[part 5 of 6: package /MICROSAR/KeyM_swc/ComponentTypes]
AUTOSAR XML (schema 00049)
package /MICROSAR/KeyM_swc/ComponentTypes  (continued)
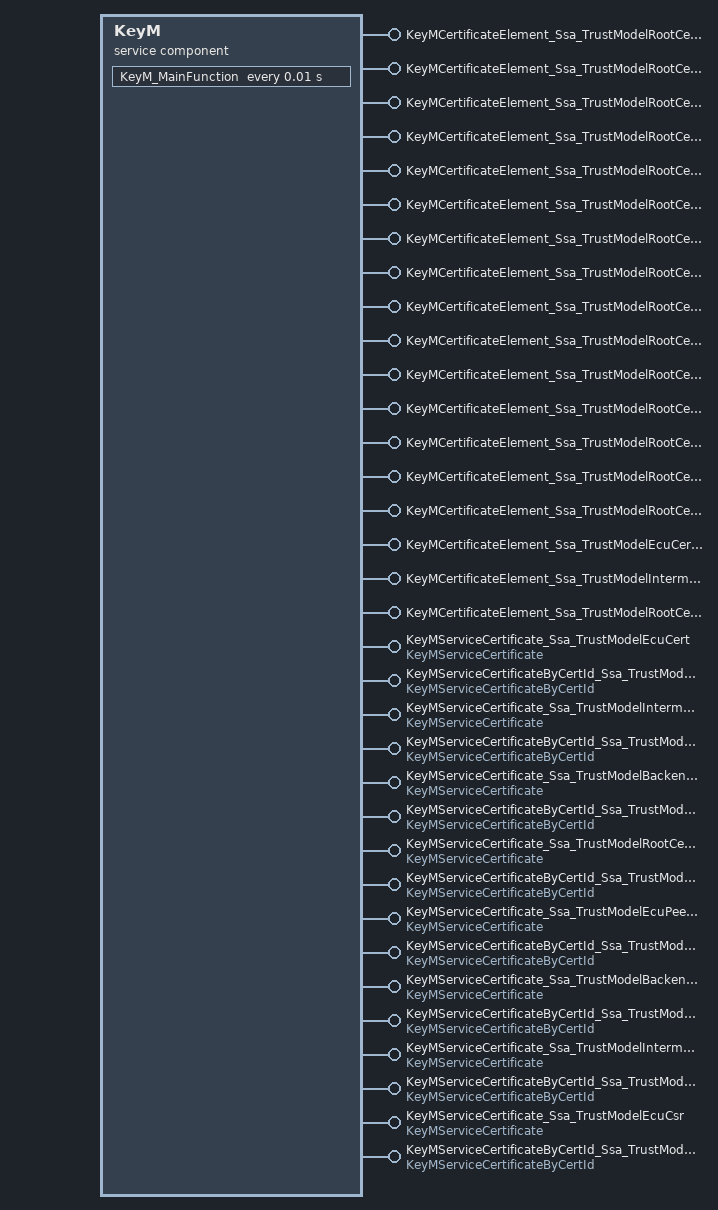
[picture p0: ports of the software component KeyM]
  service sw component type KeyM: category=SERVICE_COMPONENT  (continued)
    34 x provide port:
      KeyMCertificateElement_Ssa_TrustModelRootCert_Version: provided-interface=KeyMCertificateElement_Ssa_TrustModelRootCert_Version  # Port to execute certificate related functions.
      KeyMCertificateElement_Ssa_TrustModelRootCert_SerialNo: provided-interface=KeyMCertificateElement_Ssa_TrustModelRootCert_SerialNo  # Port to execute certificate related functions.
      KeyMCertificateElement_Ssa_TrustModelRootCert_SigAlgoId: provided-interface=KeyMCertificateElement_Ssa_TrustModelRootCert_SigAlgoId  # Port to execute certificate related functions.
      KeyMCertificateElement_Ssa_TrustModelRootCert_validityNotBefore: provided-interface=KeyMCertificateElement_Ssa_TrustModelRootCert_validityNotBefore  # Port to execute certificate related functions.
      KeyMCertificateElement_Ssa_TrustModelRootCert_validityNotAfter: provided-interface=KeyMCertificateElement_Ssa_TrustModelRootCert_validityNotAfter  # Port to execute certificate related functions.
      KeyMCertificateElement_Ssa_TrustModelRootCert_subject: provided-interface=KeyMCertificateElement_Ssa_TrustModelRootCert_subject  # Port to execute certificate related functions.
      KeyMCertificateElement_Ssa_TrustModelRootCert_SubjectPublicKeyInfoAlgo: provided-interface=KeyMCertificateElement_Ssa_TrustModelRootCert_SubjectPublicKeyInfoAlgo  # Port to execute certificate related functions.
      KeyMCertificateElement_Ssa_TrustModelRootCert_SubjectPublicKeyInfoKey: provided-interface=KeyMCertificateElement_Ssa_TrustModelRootCert_SubjectPublicKeyInfoKey  # Port to execute certificate related functions.
      KeyMCertificateElement_Ssa_TrustModelRootCert_Issuer: provided-interface=KeyMCertificateElement_Ssa_TrustModelRootCert_Issuer  # Port to execute certificate related functions.
      KeyMCertificateElement_Ssa_TrustModelRootCert_signatureAlgorithm: provided-interface=KeyMCertificateElement_Ssa_TrustModelRootCert_signatureAlgorithm  # Port to execute certificate related functions.
      KeyMCertificateElement_Ssa_TrustModelRootCert_signatureValue: provided-interface=KeyMCertificateElement_Ssa_TrustModelRootCert_signatureValue  # Port to execute certificate related functions.
      KeyMCertificateElement_Ssa_TrustModelRootCert_ext_subKeyId: provided-interface=KeyMCertificateElement_Ssa_TrustModelRootCert_ext_subKeyId  # Port to execute certificate related functions.
      KeyMCertificateElement_Ssa_TrustModelRootCert_ext_basicConstraints: provided-interface=KeyMCertificateElement_Ssa_TrustModelRootCert_ext_basicConstraints  # Port to execute certificate related functions.
      KeyMCertificateElement_Ssa_TrustModelRootCert_ext_keyUsage: provided-interface=KeyMCertificateElement_Ssa_TrustModelRootCert_ext_keyUsage  # Port to execute certificate related functions.
      KeyMCertificateElement_Ssa_TrustModelRootCert_ext_pkiRole: provided-interface=KeyMCertificateElement_Ssa_TrustModelRootCert_ext_pkiRole  # Port to execute certificate related functions.
      KeyMCertificateElement_Ssa_TrustModelEcuCert_ext_pkiRole_006: provided-interface=KeyMCertificateElement_Ssa_TrustModelEcuCert_ext_pkiRole_006  # Port to execute certificate related functions.
      KeyMCertificateElement_Ssa_TrustModelIntermediatePeerCert_ext_pkiRole_005: provided-interface=KeyMCertificateElement_Ssa_TrustModelIntermediatePeerCert_ext_pkiRole_005  # Port to execute certificate related functions.
      KeyMCertificateElement_Ssa_TrustModelRootCert_ext_authKeyId_009: provided-interface=KeyMCertificateElement_Ssa_TrustModelRootCert_ext_authKeyId_009  # Port to execute certificate related functions.
      KeyMServiceCertificate_Ssa_TrustModelEcuCert: provided-interface=KeyMServiceCertificate  # Port to execute certificate related functions.
      KeyMServiceCertificateByCertId_Ssa_TrustModelEcuCert: provided-interface=KeyMServiceCertificateByCertId  # Port to execute certificate related functions.
      KeyMServiceCertificate_Ssa_TrustModelIntermediateCert: provided-interface=KeyMServiceCertificate  # Port to execute certificate related functions.
      KeyMServiceCertificateByCertId_Ssa_TrustModelIntermediateCert: provided-interface=KeyMServiceCertificateByCertId  # Port to execute certificate related functions.
      KeyMServiceCertificate_Ssa_TrustModelBackendCert: provided-interface=KeyMServiceCertificate  # Port to execute certificate related functions.
      KeyMServiceCertificateByCertId_Ssa_TrustModelBackendCert: provided-interface=KeyMServiceCertificateByCertId  # Port to execute certificate related functions.
      KeyMServiceCertificate_Ssa_TrustModelRootCert: provided-interface=KeyMServiceCertificate  # Port to execute certificate related functions.
      KeyMServiceCertificateByCertId_Ssa_TrustModelRootCert: provided-interface=KeyMServiceCertificateByCertId  # Port to execute certificate related functions.
      KeyMServiceCertificate_Ssa_TrustModelEcuPeerCert: provided-interface=KeyMServiceCertificate  # Port to execute certificate related functions.
      KeyMServiceCertificateByCertId_Ssa_TrustModelEcuPeerCert: provided-interface=KeyMServiceCertificateByCertId  # Port to execute certificate related functions.
      KeyMServiceCertificate_Ssa_TrustModelBackendPeerCert: provided-interface=KeyMServiceCertificate  # Port to execute certificate related functions.
      KeyMServiceCertificateByCertId_Ssa_TrustModelBackendPeerCert: provided-interface=KeyMServiceCertificateByCertId  # Port to execute certificate related functions.
      KeyMServiceCertificate_Ssa_TrustModelIntermediatePeerCert: provided-interface=KeyMServiceCertificate  # Port to execute certificate related functions.
      KeyMServiceCertificateByCertId_Ssa_TrustModelIntermediatePeerCert: provided-interface=KeyMServiceCertificateByCertId  # Port to execute certificate related functions.
      KeyMServiceCertificate_Ssa_TrustModelEcuCsr: provided-interface=KeyMServiceCertificate  # Port to execute certificate related functions.
      KeyMServiceCertificateByCertId_Ssa_TrustModelEcuCsr: provided-interface=KeyMServiceCertificateByCertId  # Port to execute certificate related functions.
    behavior KeyMInternalBehavior: handle-termination-and-restart=NO-SUPPORT, included-data-type-set=data-type=[KeyM_CertElementIdType, KeyM_CertificateIdType, KeyM_const_CryptoKeyDataType, KeyM_CryptoKeyDataType, KeyM_ConstDataPtrType, KeyM_DataPtrType, KeyM_LengthPtrType, KeyM_CertDataPointerType, KeyM_CertDataType, KeyM_CsrEncodingType, KeyM_ServiceCertificateType, KeyM_CertificateStatusType, KeyM_ResultType, KeyM_CertificateDataType_Ssa_TrustModelEcuCert, KeyM_CertificateType_Ssa_TrustModelEcuCert, KeyM_CertificateElementType_Ssa_TrustModelEcuCert_ext_authKeyId_005, KeyM_CertificateElementType_Ssa_TrustModelEcuCert_ext_subKeyId_005, KeyM_CertificateElementType_Ssa_TrustModelEcuCert_ext_keyUsage_005, KeyM_CertificateElementType_Ssa_TrustModelEcuCert_ext_pkiRole_006, KeyM_CertificateElementType_Ssa_TrustModelEcuCert_Version_005, KeyM_CertificateElementType_Ssa_TrustModelEcuCert_SerialNo_005, KeyM_CertificateElementType_Ssa_TrustModelEcuCert_SigAlgoId_005, KeyM_CertificateElementType_Ssa_TrustModelEcuCert_validityNotBefore_005, KeyM_CertificateElementType_Ssa_TrustModelEcuCert_validityNotAfter_005, KeyM_CertificateElementType_Ssa_TrustModelEcuCert_subject_005, KeyM_CertificateElementType_Ssa_TrustModelEcuCert_SubjectPublicKeyInfoAlgo_005, KeyM_CertificateElementType_Ssa_TrustModelEcuCert_SubjectPublicKeyInfoKey_005, KeyM_CertificateElementType_Ssa_TrustModelEcuCert_Issuer_005, KeyM_CertificateElementType_Ssa_TrustModelEcuCert_signatureAlgorithm_005, KeyM_CertificateElementType_Ssa_TrustModelEcuCert_signatureValue_005, KeyM_CertificateElementType_Ssa_TrustModelEcuCert_ext_uniqueECUID_005, KeyM_CertificateElementType_Ssa_TrustModelEcuCert_ext_specialEcu_005, KeyM_CertificateDataType_Ssa_TrustModelIntermediateCert, KeyM_CertificateType_Ssa_TrustModelIntermediateCert, KeyM_CertificateElementType_Ssa_TrustModelIntermediateCert_ext_authKeyId_003, KeyM_CertificateElementType_Ssa_TrustModelIntermediateCert_ext_subKeyId_003, KeyM_CertificateElementType_Ssa_TrustModelIntermediateCert_ext_basicConstraints_003, KeyM_CertificateElementType_Ssa_TrustModelIntermediateCert_ext_keyUsage_003, KeyM_CertificateElementType_Ssa_TrustModelIntermediateCert_ext_pkiRole_003, KeyM_CertificateElementType_Ssa_TrustModelIntermediateCert_Version_003, KeyM_CertificateElementType_Ssa_TrustModelIntermediateCert_SerialNo_003, KeyM_CertificateElementType_Ssa_TrustModelIntermediateCert_SigAlgoId_003, KeyM_CertificateElementType_Ssa_TrustModelIntermediateCert_validityNotBefore_003, KeyM_CertificateElementType_Ssa_TrustModelIntermediateCert_validityNotAfter_003, KeyM_CertificateElementType_Ssa_TrustModelIntermediateCert_subject_003, KeyM_CertificateElementType_Ssa_TrustModelIntermediateCert_SubjectPublicKeyInfoAlgo_003, KeyM_CertificateElementType_Ssa_TrustModelIntermediateCert_SubjectPublicKeyInfoKey_003, KeyM_CertificateElementType_Ssa_TrustModelIntermediateCert_Issuer_003, KeyM_CertificateElementType_Ssa_TrustModelIntermediateCert_signatureAlgorithm_003, KeyM_CertificateElementType_Ssa_TrustModelIntermediateCert_signatureValue_003, KeyM_CertificateDataType_Ssa_TrustModelBackendCert, KeyM_CertificateType_Ssa_TrustModelBackendCert, KeyM_CertificateElementType_Ssa_TrustModelBackendCert_ext_authKeyId_002, KeyM_CertificateElementType_Ssa_TrustModelBackendCert_ext_subKeyId_002, KeyM_CertificateElementType_Ssa_TrustModelBackendCert_ext_basicConstraints_002, KeyM_CertificateElementType_Ssa_TrustModelBackendCert_ext_keyUsage_002, KeyM_CertificateElementType_Ssa_TrustModelBackendCert_ext_pkiRole_002, KeyM_CertificateElementType_Ssa_TrustModelBackendCert_Version_002, KeyM_CertificateElementType_Ssa_TrustModelBackendCert_SerialNo_002, KeyM_CertificateElementType_Ssa_TrustModelBackendCert_SigAlgoId_002, KeyM_CertificateElementType_Ssa_TrustModelBackendCert_validityNotBefore_002, KeyM_CertificateElementType_Ssa_TrustModelBackendCert_validityNotAfter_002, KeyM_CertificateElementType_Ssa_TrustModelBackendCert_subject_002, KeyM_CertificateElementType_Ssa_TrustModelBackendCert_SubjectPublicKeyInfoAlgo_002, KeyM_CertificateElementType_Ssa_TrustModelBackendCert_SubjectPublicKeyInfoKey_002, KeyM_CertificateElementType_Ssa_TrustModelBackendCert_Issuer_002, KeyM_CertificateElementType_Ssa_TrustModelBackendCert_signatureAlgorithm_002, KeyM_CertificateElementType_Ssa_TrustModelBackendCert_signatureValue_002, KeyM_CertificateDataType_Ssa_TrustModelRootCert, KeyM_CertificateType_Ssa_TrustModelRootCert, KeyM_CertificateElementType_Ssa_TrustModelRootCert_ext_authKeyId_009, KeyM_CertificateElementType_Ssa_TrustModelRootCert_Version, KeyM_CertificateElementType_Ssa_TrustModelRootCert_SerialNo, KeyM_CertificateElementType_Ssa_TrustModelRootCert_SigAlgoId, KeyM_CertificateElementType_Ssa_TrustModelRootCert_validityNotBefore, KeyM_CertificateElementType_Ssa_TrustModelRootCert_validityNotAfter, KeyM_CertificateElementType_Ssa_TrustModelRootCert_subject, KeyM_CertificateElementType_Ssa_TrustModelRootCert_SubjectPublicKeyInfoAlgo, KeyM_CertificateElementType_Ssa_TrustModelRootCert_SubjectPublicKeyInfoKey, KeyM_CertificateElementType_Ssa_TrustModelRootCert_Issuer, KeyM_CertificateElementType_Ssa_TrustModelRootCert_signatureAlgorithm, KeyM_CertificateElementType_Ssa_TrustModelRootCert_signatureValue, KeyM_CertificateElementType_Ssa_TrustModelRootCert_ext_subKeyId, KeyM_CertificateElementType_Ssa_TrustModelRootCert_ext_basicConstraints, KeyM_CertificateElementType_Ssa_TrustModelRootCert_ext_keyUsage, KeyM_CertificateElementType_Ssa_TrustModelRootCert_ext_pkiRole, KeyM_CertificateDataType_Ssa_TrustModelEcuPeerCert, KeyM_CertificateType_Ssa_TrustModelEcuPeerCert, KeyM_CertificateElementType_Ssa_TrustModelEcuPeerCert_ext_authKeyId_006, KeyM_CertificateElementType_Ssa_TrustModelEcuPeerCert_ext_subKeyId_006, KeyM_CertificateElementType_Ssa_TrustModelEcuPeerCert_ext_keyUsage_006, KeyM_CertificateElementType_Ssa_TrustModelEcuPeerCert_Version_006, KeyM_CertificateElementType_Ssa_TrustModelEcuPeerCert_SerialNo_006, KeyM_CertificateElementType_Ssa_TrustModelEcuPeerCert_SigAlgoId_006, KeyM_CertificateElementType_Ssa_TrustModelEcuPeerCert_validityNotBefore_006, KeyM_CertificateElementType_Ssa_TrustModelEcuPeerCert_validityNotAfter_006, KeyM_CertificateElementType_Ssa_TrustModelEcuPeerCert_subject_006, KeyM_CertificateElementType_Ssa_TrustModelEcuPeerCert_SubjectPublicKeyInfoAlgo_006, KeyM_CertificateElementType_Ssa_TrustModelEcuPeerCert_SubjectPublicKeyInfoKey_006, KeyM_CertificateElementType_Ssa_TrustModelEcuPeerCert_Issuer_006, KeyM_CertificateElementType_Ssa_TrustModelEcuPeerCert_signatureAlgorithm_006, KeyM_CertificateElementType_Ssa_TrustModelEcuPeerCert_signatureValue_006, KeyM_CertificateElementType_Ssa_TrustModelEcuPeerCert_ext_uniqueECUID_006, KeyM_CertificateElementType_Ssa_TrustModelEcuPeerCert_ext_specialEcu_006, KeyM_CertificateDataType_Ssa_TrustModelBackendPeerCert, KeyM_CertificateType_Ssa_TrustModelBackendPeerCert, KeyM_CertificateElementType_Ssa_TrustModelBackendPeerCert_ext_authKeyId_004, KeyM_CertificateElementType_Ssa_TrustModelBackendPeerCert_ext_subKeyId_004, KeyM_CertificateElementType_Ssa_TrustModelBackendPeerCert_ext_basicConstraints_004, KeyM_CertificateElementType_Ssa_TrustModelBackendPeerCert_ext_keyUsage_004, KeyM_CertificateElementType_Ssa_TrustModelBackendPeerCert_ext_pkiRole_004, KeyM_CertificateElementType_Ssa_TrustModelBackendPeerCert_Version_004, KeyM_CertificateElementType_Ssa_TrustModelBackendPeerCert_SerialNo_004, KeyM_CertificateElementType_Ssa_TrustModelBackendPeerCert_SigAlgoId_004, KeyM_CertificateElementType_Ssa_TrustModelBackendPeerCert_validityNotBefore_004, KeyM_CertificateElementType_Ssa_TrustModelBackendPeerCert_validityNotAfter_004, KeyM_CertificateElementType_Ssa_TrustModelBackendPeerCert_subject_004, KeyM_CertificateElementType_Ssa_TrustModelBackendPeerCert_SubjectPublicKeyInfoAlgo_004, KeyM_CertificateElementType_Ssa_TrustModelBackendPeerCert_SubjectPublicKeyInfoKey_004, KeyM_CertificateElementType_Ssa_TrustModelBackendPeerCert_Issuer_004, KeyM_CertificateElementType_Ssa_TrustModelBackendPeerCert_signatureAlgorithm_004, KeyM_CertificateElementType_Ssa_TrustModelBackendPeerCert_signatureValue_004, KeyM_CertificateDataType_Ssa_TrustModelIntermediatePeerCert, KeyM_CertificateType_Ssa_TrustModelIntermediatePeerCert, KeyM_CertificateElementType_Ssa_TrustModelIntermediatePeerCert_ext_authKeyId_007, KeyM_CertificateElementType_Ssa_TrustModelIntermediatePeerCert_ext_subKeyId_007, KeyM_CertificateElementType_Ssa_TrustModelIntermediatePeerCert_ext_basicConstraints_005, KeyM_CertificateElementType_Ssa_TrustModelIntermediatePeerCert_ext_keyUsage_007, KeyM_CertificateElementType_Ssa_TrustModelIntermediatePeerCert_ext_pkiRole_005, KeyM_CertificateElementType_Ssa_TrustModelIntermediatePeerCert_Version_007, KeyM_CertificateElementType_Ssa_TrustModelIntermediatePeerCert_SerialNo_007, KeyM_CertificateElementType_Ssa_TrustModelIntermediatePeerCert_SigAlgoId_007, KeyM_CertificateElementType_Ssa_TrustModelIntermediatePeerCert_validityNotBefore_007, KeyM_CertificateElementType_Ssa_TrustModelIntermediatePeerCert_validityNotAfter_007, KeyM_CertificateElementType_Ssa_TrustModelIntermediatePeerCert_subject_007, KeyM_CertificateElementType_Ssa_TrustModelIntermediatePeerCert_SubjectPublicKeyInfoAlgo_007, KeyM_CertificateElementType_Ssa_TrustModelIntermediatePeerCert_SubjectPublicKeyInfoKey_007, KeyM_CertificateElementType_Ssa_TrustModelIntermediatePeerCert_Issuer_007, KeyM_CertificateElementType_Ssa_TrustModelIntermediatePeerCert_signatureAlgorithm_007, KeyM_CertificateElementType_Ssa_TrustModelIntermediatePeerCert_signatureValue_007, KeyM_CertificateDataType_Ssa_TrustModelEcuCsr, KeyM_CertificateType_Ssa_TrustModelEcuCsr, KeyM_CertificateElementType_Ssa_TrustModelEcuCsr_ext_authKeyId_008, KeyM_CertificateElementType_Ssa_TrustModelEcuCsr_ext_subKeyId_008, KeyM_CertificateElementType_Ssa_TrustModelEcuCsr_ext_keyUsage_008, KeyM_CertificateElementType_Ssa_TrustModelEcuCsr_ext_pkiRole_008, KeyM_CertificateElementType_Ssa_TrustModelEcuCsr_Version_008, KeyM_CertificateElementType_Ssa_TrustModelEcuCsr_SerialNo_008, KeyM_CertificateElementType_Ssa_TrustModelEcuCsr_SigAlgoId_008, KeyM_CertificateElementType_Ssa_TrustModelEcuCsr_validityNotBefore_008, KeyM_CertificateElementType_Ssa_TrustModelEcuCsr_validityNotAfter_008, KeyM_CertificateElementType_Ssa_TrustModelEcuCsr_subject_008, KeyM_CertificateElementType_Ssa_TrustModelEcuCsr_SubjectPublicKeyInfoAlgo_008, KeyM_CertificateElementType_Ssa_TrustModelEcuCsr_SubjectPublicKeyInfoKey_008, KeyM_CertificateElementType_Ssa_TrustModelEcuCsr_Issuer_008, KeyM_CertificateElementType_Ssa_TrustModelEcuCsr_signatureAlgorithm_008, KeyM_CertificateElementType_Ssa_TrustModelEcuCsr_signatureValue_008, KeyM_CertificateElementType_Ssa_TrustModelEcuCsr_ext_uniqueECUID_007, KeyM_CertificateElementType_Ssa_TrustModelEcuCsr_ext_specialEcu_007, KeyM_CertificateElementType_Ssa_TrustModelEcuCsr_ext_extKeyUsage_007, KeyM_CertificateElementType_Ssa_TrustModelEcuCsr_ext_extKeyUsage_oid1_007, KeyM_CertificateElementType_Ssa_TrustModelEcuCsr_ext_extKeyUsage_oid2_007, KeyM_CertificateElementType_Ssa_TrustModelEcuCsr_ext_extKeyUsage_oid3_007]
      timing event Timer_KeyM_MainFunction: start-on-event=KeyM_MainFunction, period=0.01
      466 x operation invoked event:
        OpEventGetCertificate_Ssa_TrustModelBackendCert_GetCertificate_KeyMCertificate_Ssa_TrustModelBackendCert: start-on-event=GetCertificate_Ssa_TrustModelBackendCert, operation=KeyMCertificate_Ssa_TrustModelBackendCert.GetCertificate
        OpEventCertificateElementGetCount_CertificateElementGetCount_KeyMCertificateElement_Ssa_TrustModelIntermediatePeerCert_b8bfbe9c: start-on-event=CertificateElementGetCount, operation=KeyMCertificateElement_Ssa_TrustModelIntermediatePeerCert_SubjectPublicKeyInfoAlgo_007.CertificateElementGetCount
        OpEventCertificateElementGetCount_CertificateElementGetCount_KeyMCertificateElement_Ssa_TrustModelEcuCert_signatureAlgorithm_005: start-on-event=CertificateElementGetCount, operation=KeyMCertificateElement_Ssa_TrustModelEcuCert_signatureAlgorithm_005.CertificateElementGetCount
        OpEventCertificateElementGetCount_CertificateElementGetCount_KeyMCertificateElement_Ssa_TrustModelEcuCsr_ext_specialEcu_007: start-on-event=CertificateElementGetCount, operation=KeyMCertificateElement_Ssa_TrustModelEcuCsr_ext_specialEcu_007.CertificateElementGetCount
        OpEventCertificateElementGetCount_CertificateElementGetCount_KeyMCertificateElement_Ssa_TrustModelEcuPeerCert_ext_keyUsage_006: start-on-event=CertificateElementGetCount, operation=KeyMCertificateElement_Ssa_TrustModelEcuPeerCert_ext_keyUsage_006.CertificateElementGetCount
        OpEventCertificateElementGetCount_CertificateElementGetCount_KeyMCertificateElement_Ssa_TrustModelEcuCsr_ext_authKeyId_008: start-on-event=CertificateElementGetCount, operation=KeyMCertificateElement_Ssa_TrustModelEcuCsr_ext_authKeyId_008.CertificateElementGetCount
        OpEventCertificateElementGetCount_CertificateElementGetCount_KeyMCertificateElement_Ssa_TrustModelEcuCsr_SerialNo_008: start-on-event=CertificateElementGetCount, operation=KeyMCertificateElement_Ssa_TrustModelEcuCsr_SerialNo_008.CertificateElementGetCount
        OpEventCertificateElementGetCount_CertificateElementGetCount_KeyMCertificateElement_Ssa_TrustModelIntermediatePeerCert_69e38857: start-on-event=CertificateElementGetCount, operation=KeyMCertificateElement_Ssa_TrustModelIntermediatePeerCert_Issuer_007.CertificateElementGetCount
        OpEventCertificateElementGetCount_CertificateElementGetCount_KeyMCertificateElement_Ssa_TrustModelIntermediatePeerCert_981aecb6: start-on-event=CertificateElementGetCount, operation=KeyMCertificateElement_Ssa_TrustModelIntermediatePeerCert_ext_subKeyId_007.CertificateElementGetCount
        OpEventCertificateElementGetCount_CertificateElementGetCount_KeyMCertificateElement_Ssa_TrustModelBackendPeerCert_Version_004: start-on-event=CertificateElementGetCount, operation=KeyMCertificateElement_Ssa_TrustModelBackendPeerCert_Version_004.CertificateElementGetCount
        OpEventCertificateElementGetCount_CertificateElementGetCount_KeyMCertificateElement_Ssa_TrustModelIntermediatePeerCert_14bdc58e: start-on-event=CertificateElementGetCount, operation=KeyMCertificateElement_Ssa_TrustModelIntermediatePeerCert_subject_007.CertificateElementGetCount
        OpEventCertificateElementGetCount_CertificateElementGetCount_KeyMCertificateElement_Ssa_TrustModelBackendCert_ext_authKeyId_002: start-on-event=CertificateElementGetCount, operation=KeyMCertificateElement_Ssa_TrustModelBackendCert_ext_authKeyId_002.CertificateElementGetCount
        OpEventCertificateElementGetCount_CertificateElementGetCount_KeyMCertificateElement_Ssa_TrustModelIntermediateCert_Version_003: start-on-event=CertificateElementGetCount, operation=KeyMCertificateElement_Ssa_TrustModelIntermediateCert_Version_003.CertificateElementGetCount
        OpEventCertificateElementGetCount_CertificateElementGetCount_KeyMCertificateElement_Ssa_TrustModelBackendCert_SubjectPu_e89d2572: start-on-event=CertificateElementGetCount, operation=KeyMCertificateElement_Ssa_TrustModelBackendCert_SubjectPublicKeyInfoKey_002.CertificateElementGetCount
        OpEventCertificateElementGetCount_CertificateElementGetCount_KeyMCertificateElement_Ssa_TrustModelEcuCsr_SubjectPublicK_4f39b0de: start-on-event=CertificateElementGetCount, operation=KeyMCertificateElement_Ssa_TrustModelEcuCsr_SubjectPublicKeyInfoKey_008.CertificateElementGetCount
        OpEventCertificateElementGetCount_CertificateElementGetCount_KeyMCertificateElement_Ssa_TrustModelBackendPeerCert_ext_a_7070e89e: start-on-event=CertificateElementGetCount, operation=KeyMCertificateElement_Ssa_TrustModelBackendPeerCert_ext_authKeyId_004.CertificateElementGetCount
        OpEventCertificateElementGetCount_CertificateElementGetCount_KeyMCertificateElement_Ssa_TrustModelBackendCert_validityN_9a428a85: start-on-event=CertificateElementGetCount, operation=KeyMCertificateElement_Ssa_TrustModelBackendCert_validityNotAfter_002.CertificateElementGetCount
        OpEventCertificateElementGetCount_CertificateElementGetCount_KeyMCertificateElement_Ssa_TrustModelIntermediateCert_Subj_7b37ce18: start-on-event=CertificateElementGetCount, operation=KeyMCertificateElement_Ssa_TrustModelIntermediateCert_SubjectPublicKeyInfoAlgo_003.CertificateElementGetCount
        OpEventCertificateElementGetCount_CertificateElementGetCount_KeyMCertificateElement_Ssa_TrustModelBackendCert_signature_37dbcc1b: start-on-event=CertificateElementGetCount, operation=KeyMCertificateElement_Ssa_TrustModelBackendCert_signatureAlgorithm_002.CertificateElementGetCount
        OpEventCertificateElementGetCount_CertificateElementGetCount_KeyMCertificateElement_Ssa_TrustModelIntermediateCert_SerialNo_003: start-on-event=CertificateElementGetCount, operation=KeyMCertificateElement_Ssa_TrustModelIntermediateCert_SerialNo_003.CertificateElementGetCount
        OpEventCertificateElementGetCount_CertificateElementGetCount_KeyMCertificateElement_Ssa_TrustModelIntermediateCert_ext_6b458183: start-on-event=CertificateElementGetCount, operation=KeyMCertificateElement_Ssa_TrustModelIntermediateCert_ext_basicConstraints_003.CertificateElementGetCount
        OpEventCertificateElementGetCount_CertificateElementGetCount_KeyMCertificateElement_Ssa_TrustModelEcuCert_Issuer_005: start-on-event=CertificateElementGetCount, operation=KeyMCertificateElement_Ssa_TrustModelEcuCert_Issuer_005.CertificateElementGetCount
        OpEventCertificateElementGetCount_CertificateElementGetCount_KeyMCertificateElement_Ssa_TrustModelEcuPeerCert_ext_uniqu_19d8752c: start-on-event=CertificateElementGetCount, operation=KeyMCertificateElement_Ssa_TrustModelEcuPeerCert_ext_uniqueECUID_006.CertificateElementGetCount
        OpEventCertificateElementGetCount_CertificateElementGetCount_KeyMCertificateElement_Ssa_TrustModelBackendCert_SigAlgoId_002: start-on-event=CertificateElementGetCount, operation=KeyMCertificateElement_Ssa_TrustModelBackendCert_SigAlgoId_002.CertificateElementGetCount
        OpEventCertificateElementGetCount_CertificateElementGetCount_KeyMCertificateElement_Ssa_TrustModelBackendCert_ext_subKeyId_002: start-on-event=CertificateElementGetCount, operation=KeyMCertificateElement_Ssa_TrustModelBackendCert_ext_subKeyId_002.CertificateElementGetCount
        OpEventCertificateElementGetCount_CertificateElementGetCount_KeyMCertificateElement_Ssa_TrustModelBackendCert_subject_002: start-on-event=CertificateElementGetCount, operation=KeyMCertificateElement_Ssa_TrustModelBackendCert_subject_002.CertificateElementGetCount
        OpEventCertificateElementGetCount_CertificateElementGetCount_KeyMCertificateElement_Ssa_TrustModelBackendPeerCert_ext_k_87711b19: start-on-event=CertificateElementGetCount, operation=KeyMCertificateElement_Ssa_TrustModelBackendPeerCert_ext_keyUsage_004.CertificateElementGetCount
        OpEventCertificateElementGetCount_CertificateElementGetCount_KeyMCertificateElement_Ssa_TrustModelBackendPeerCert_Subje_4bbc2c66: start-on-event=CertificateElementGetCount, operation=KeyMCertificateElement_Ssa_TrustModelBackendPeerCert_SubjectPublicKeyInfoKey_004.CertificateElementGetCount
        OpEventCertificateElementGetCount_CertificateElementGetCount_KeyMCertificateElement_Ssa_TrustModelEcuCsr_validityNotAfter_008: start-on-event=CertificateElementGetCount, operation=KeyMCertificateElement_Ssa_TrustModelEcuCsr_validityNotAfter_008.CertificateElementGetCount
        OpEventCertificateElementGetCount_CertificateElementGetCount_KeyMCertificateElement_Ssa_TrustModelEcuCert_validityNotBefore_005: start-on-event=CertificateElementGetCount, operation=KeyMCertificateElement_Ssa_TrustModelEcuCert_validityNotBefore_005.CertificateElementGetCount
        OpEventCertificateElementGetCount_CertificateElementGetCount_KeyMCertificateElement_Ssa_TrustModelBackendPeerCert_subject_004: start-on-event=CertificateElementGetCount, operation=KeyMCertificateElement_Ssa_TrustModelBackendPeerCert_subject_004.CertificateElementGetCount
        OpEventCertificateElementGetCount_CertificateElementGetCount_KeyMCertificateElement_Ssa_TrustModelBackendPeerCert_SigAlgoId_004: start-on-event=CertificateElementGetCount, operation=KeyMCertificateElement_Ssa_TrustModelBackendPeerCert_SigAlgoId_004.CertificateElementGetCount
        OpEventCertificateElementGetCount_CertificateElementGetCount_KeyMCertificateElement_Ssa_TrustModelIntermediateCert_sign_5f19d28f: start-on-event=CertificateElementGetCount, operation=KeyMCertificateElement_Ssa_TrustModelIntermediateCert_signatureAlgorithm_003.CertificateElementGetCount
        OpEventCertificateElementGetCount_CertificateElementGetCount_KeyMCertificateElement_Ssa_TrustModelIntermediatePeerCert_7df9f6ad: start-on-event=CertificateElementGetCount, operation=KeyMCertificateElement_Ssa_TrustModelIntermediatePeerCert_validityNotAfter_007.CertificateElementGetCount
        OpEventCertificateElementGetCount_CertificateElementGetCount_KeyMCertificateElement_Ssa_TrustModelIntermediateCert_Issuer_003: start-on-event=CertificateElementGetCount, operation=KeyMCertificateElement_Ssa_TrustModelIntermediateCert_Issuer_003.CertificateElementGetCount
        OpEventCertificateElementGetCount_CertificateElementGetCount_KeyMCertificateElement_Ssa_TrustModelBackendPeerCert_Subje_cca0c35e: start-on-event=CertificateElementGetCount, operation=KeyMCertificateElement_Ssa_TrustModelBackendPeerCert_SubjectPublicKeyInfoAlgo_004.CertificateElementGetCount
        OpEventCertificateElementGetCount_CertificateElementGetCount_KeyMCertificateElement_Ssa_TrustModelEcuPeerCert_validityN_7ebdb999: start-on-event=CertificateElementGetCount, operation=KeyMCertificateElement_Ssa_TrustModelEcuPeerCert_validityNotAfter_006.CertificateElementGetCount
        OpEventCertificateElementGetCount_CertificateElementGetCount_KeyMCertificateElement_Ssa_TrustModelIntermediatePeerCert_a514cd03: start-on-event=CertificateElementGetCount, operation=KeyMCertificateElement_Ssa_TrustModelIntermediatePeerCert_ext_basicConstraints_005.CertificateElementGetCount
        OpEventCertificateElementGetCount_CertificateElementGetCount_KeyMCertificateElement_Ssa_TrustModelEcuCsr_ext_pkiRole_008: start-on-event=CertificateElementGetCount, operation=KeyMCertificateElement_Ssa_TrustModelEcuCsr_ext_pkiRole_008.CertificateElementGetCount
        OpEventCertificateElementGetCount_CertificateElementGetCount_KeyMCertificateElement_Ssa_TrustModelBackendPeerCert_Issuer_004: start-on-event=CertificateElementGetCount, operation=KeyMCertificateElement_Ssa_TrustModelBackendPeerCert_Issuer_004.CertificateElementGetCount
        OpEventCertificateElementGetCount_CertificateElementGetCount_KeyMCertificateElement_Ssa_TrustModelEcuPeerCert_SerialNo_006: start-on-event=CertificateElementGetCount, operation=KeyMCertificateElement_Ssa_TrustModelEcuPeerCert_SerialNo_006.CertificateElementGetCount
        OpEventCertificateElementGetCount_CertificateElementGetCount_KeyMCertificateElement_Ssa_TrustModelEcuCert_signatureValue_005: start-on-event=CertificateElementGetCount, operation=KeyMCertificateElement_Ssa_TrustModelEcuCert_signatureValue_005.CertificateElementGetCount
        OpEventCertificateElementGetCount_CertificateElementGetCount_KeyMCertificateElement_Ssa_TrustModelBackendPeerCert_SerialNo_004: start-on-event=CertificateElementGetCount, operation=KeyMCertificateElement_Ssa_TrustModelBackendPeerCert_SerialNo_004.CertificateElementGetCount
        OpEventCertificateElementGetCount_CertificateElementGetCount_KeyMCertificateElement_Ssa_TrustModelEcuCert_ext_specialEcu_005: start-on-event=CertificateElementGetCount, operation=KeyMCertificateElement_Ssa_TrustModelEcuCert_ext_specialEcu_005.CertificateElementGetCount
        OpEventCertificateElementGetCount_CertificateElementGetCount_KeyMCertificateElement_Ssa_TrustModelEcuCert_ext_authKeyId_005: start-on-event=CertificateElementGetCount, operation=KeyMCertificateElement_Ssa_TrustModelEcuCert_ext_authKeyId_005.CertificateElementGetCount
        OpEventCertificateElementGetCount_CertificateElementGetCount_KeyMCertificateElement_Ssa_TrustModelEcuPeerCert_validityN_02cfe267: start-on-event=CertificateElementGetCount, operation=KeyMCertificateElement_Ssa_TrustModelEcuPeerCert_validityNotBefore_006.CertificateElementGetCount
        OpEventCertificateElementGetCount_CertificateElementGetCount_KeyMCertificateElement_Ssa_TrustModelEcuCsr_ext_subKeyId_008: start-on-event=CertificateElementGetCount, operation=KeyMCertificateElement_Ssa_TrustModelEcuCsr_ext_subKeyId_008.CertificateElementGetCount
        OpEventCertificateElementGetCount_CertificateElementGetCount_KeyMCertificateElement_Ssa_TrustModelIntermediateCert_sign_e7bcb03d: start-on-event=CertificateElementGetCount, operation=KeyMCertificateElement_Ssa_TrustModelIntermediateCert_signatureValue_003.CertificateElementGetCount
        OpEventCertificateElementGetCount_CertificateElementGetCount_KeyMCertificateElement_Ssa_TrustModelBackendPeerCert_ext_b_b7c33782: start-on-event=CertificateElementGetCount, operation=KeyMCertificateElement_Ssa_TrustModelBackendPeerCert_ext_basicConstraints_004.CertificateElementGetCount
        OpEventCertificateElementGetCount_CertificateElementGetCount_KeyMCertificateElement_Ssa_TrustModelBackendPeerCert_signa_7fc2525c: start-on-event=CertificateElementGetCount, operation=KeyMCertificateElement_Ssa_TrustModelBackendPeerCert_signatureAlgorithm_004.CertificateElementGetCount
        OpEventCertificateElementGetCount_CertificateElementGetCount_KeyMCertificateElement_Ssa_TrustModelBackendCert_signatureValue_002: start-on-event=CertificateElementGetCount, operation=KeyMCertificateElement_Ssa_TrustModelBackendCert_signatureValue_002.CertificateElementGetCount
        OpEventCertificateElementGetCount_CertificateElementGetCount_KeyMCertificateElement_Ssa_TrustModelEcuCsr_Version_008: start-on-event=CertificateElementGetCount, operation=KeyMCertificateElement_Ssa_TrustModelEcuCsr_Version_008.CertificateElementGetCount
        OpEventCertificateElementGetCount_CertificateElementGetCount_KeyMCertificateElement_Ssa_TrustModelEcuCert_SerialNo_005: start-on-event=CertificateElementGetCount, operation=KeyMCertificateElement_Ssa_TrustModelEcuCert_SerialNo_005.CertificateElementGetCount
        OpEventCertificateElementGetCount_CertificateElementGetCount_KeyMCertificateElement_Ssa_TrustModelIntermediatePeerCert_6997f770: start-on-event=CertificateElementGetCount, operation=KeyMCertificateElement_Ssa_TrustModelIntermediatePeerCert_ext_keyUsage_007.CertificateElementGetCount
        OpEventCertificateElementGetCount_CertificateElementGetCount_KeyMCertificateElement_Ssa_TrustModelEcuCsr_signatureAlgorithm_008: start-on-event=CertificateElementGetCount, operation=KeyMCertificateElement_Ssa_TrustModelEcuCsr_signatureAlgorithm_008.CertificateElementGetCount
        OpEventCertificateElementGetCount_CertificateElementGetCount_KeyMCertificateElement_Ssa_TrustModelBackendCert_validityN_752b4006: start-on-event=CertificateElementGetCount, operation=KeyMCertificateElement_Ssa_TrustModelBackendCert_validityNotBefore_002.CertificateElementGetCount
        OpEventCertificateElementGetCount_CertificateElementGetCount_KeyMCertificateElement_Ssa_TrustModelEcuPeerCert_signatureValue_006: start-on-event=CertificateElementGetCount, operation=KeyMCertificateElement_Ssa_TrustModelEcuPeerCert_signatureValue_006.CertificateElementGetCount
        OpEventCertificateElementGetCount_CertificateElementGetCount_KeyMCertificateElement_Ssa_TrustModelBackendCert_Issuer_002: start-on-event=CertificateElementGetCount, operation=KeyMCertificateElement_Ssa_TrustModelBackendCert_Issuer_002.CertificateElementGetCount
        OpEventCertificateElementGetCount_CertificateElementGetCount_KeyMCertificateElement_Ssa_TrustModelIntermediatePeerCert_928968b2: start-on-event=CertificateElementGetCount, operation=KeyMCertificateElement_Ssa_TrustModelIntermediatePeerCert_SerialNo_007.CertificateElementGetCount
        OpEventCertificateElementGetCount_CertificateElementGetCount_KeyMCertificateElement_Ssa_TrustModelEcuCsr_ext_extKeyUsag_c5da8f87: start-on-event=CertificateElementGetCount, operation=KeyMCertificateElement_Ssa_TrustModelEcuCsr_ext_extKeyUsage_oid2_007.CertificateElementGetCount
        OpEventCertificateElementGetCount_CertificateElementGetCount_KeyMCertificateElement_Ssa_TrustModelEcuCsr_ext_extKeyUsage_007: start-on-event=CertificateElementGetCount, operation=KeyMCertificateElement_Ssa_TrustModelEcuCsr_ext_extKeyUsage_007.CertificateElementGetCount
        OpEventCertificateElementGetCount_CertificateElementGetCount_KeyMCertificateElement_Ssa_TrustModelIntermediateCert_SigAlgoId_003: start-on-event=CertificateElementGetCount, operation=KeyMCertificateElement_Ssa_TrustModelIntermediateCert_SigAlgoId_003.CertificateElementGetCount
        OpEventCertificateElementGetCount_CertificateElementGetCount_KeyMCertificateElement_Ssa_TrustModelEcuCert_ext_subKeyId_005: start-on-event=CertificateElementGetCount, operation=KeyMCertificateElement_Ssa_TrustModelEcuCert_ext_subKeyId_005.CertificateElementGetCount
        OpEventCertificateElementGetCount_CertificateElementGetCount_KeyMCertificateElement_Ssa_TrustModelIntermediateCert_Subj_ff89c4bc: start-on-event=CertificateElementGetCount, operation=KeyMCertificateElement_Ssa_TrustModelIntermediateCert_SubjectPublicKeyInfoKey_003.CertificateElementGetCount
        OpEventCertificateElementGetCount_CertificateElementGetCount_KeyMCertificateElement_Ssa_TrustModelBackendPeerCert_valid_37e0e992: start-on-event=CertificateElementGetCount, operation=KeyMCertificateElement_Ssa_TrustModelBackendPeerCert_validityNotBefore_004.CertificateElementGetCount
        OpEventCertificateElementGetCount_CertificateElementGetCount_KeyMCertificateElement_Ssa_TrustModelIntermediatePeerCert_328d41e1: start-on-event=CertificateElementGetCount, operation=KeyMCertificateElement_Ssa_TrustModelIntermediatePeerCert_signatureValue_007.CertificateElementGetCount
        OpEventCertificateElementGetCount_CertificateElementGetCount_KeyMCertificateElement_Ssa_TrustModelBackendPeerCert_ext_s_76fc00df: start-on-event=CertificateElementGetCount, operation=KeyMCertificateElement_Ssa_TrustModelBackendPeerCert_ext_subKeyId_004.CertificateElementGetCount
        OpEventCertificateElementGetCount_CertificateElementGetCount_KeyMCertificateElement_Ssa_TrustModelBackendCert_ext_basic_f2a2c19d: start-on-event=CertificateElementGetCount, operation=KeyMCertificateElement_Ssa_TrustModelBackendCert_ext_basicConstraints_002.CertificateElementGetCount
        OpEventCertificateElementGetCount_CertificateElementGetCount_KeyMCertificateElement_Ssa_TrustModelIntermediateCert_ext_f14f349e: start-on-event=CertificateElementGetCount, operation=KeyMCertificateElement_Ssa_TrustModelIntermediateCert_ext_subKeyId_003.CertificateElementGetCount
        OpEventCertificateElementGetCount_CertificateElementGetCount_KeyMCertificateElement_Ssa_TrustModelIntermediateCert_vali_1d811c43: start-on-event=CertificateElementGetCount, operation=KeyMCertificateElement_Ssa_TrustModelIntermediateCert_validityNotBefore_003.CertificateElementGetCount
        OpEventCertificateElementGetCount_CertificateElementGetCount_KeyMCertificateElement_Ssa_TrustModelIntermediateCert_vali_9aaa07c0: start-on-event=CertificateElementGetCount, operation=KeyMCertificateElement_Ssa_TrustModelIntermediateCert_validityNotAfter_003.CertificateElementGetCount
        OpEventCertificateElementGetCount_CertificateElementGetCount_KeyMCertificateElement_Ssa_TrustModelBackendCert_ext_keyUsage_002: start-on-event=CertificateElementGetCount, operation=KeyMCertificateElement_Ssa_TrustModelBackendCert_ext_keyUsage_002.CertificateElementGetCount
        OpEventCertificateElementGetCount_CertificateElementGetCount_KeyMCertificateElement_Ssa_TrustModelEcuPeerCert_subject_006: start-on-event=CertificateElementGetCount, operation=KeyMCertificateElement_Ssa_TrustModelEcuPeerCert_subject_006.CertificateElementGetCount
        OpEventCertificateElementGetCount_CertificateElementGetCount_KeyMCertificateElement_Ssa_TrustModelEcuPeerCert_Issuer_006: start-on-event=CertificateElementGetCount, operation=KeyMCertificateElement_Ssa_TrustModelEcuPeerCert_Issuer_006.CertificateElementGetCount
        OpEventCertificateElementGetCount_CertificateElementGetCount_KeyMCertificateElement_Ssa_TrustModelEcuPeerCert_ext_authKeyId_006: start-on-event=CertificateElementGetCount, operation=KeyMCertificateElement_Ssa_TrustModelEcuPeerCert_ext_authKeyId_006.CertificateElementGetCount
        OpEventCertificateElementGetCount_CertificateElementGetCount_KeyMCertificateElement_Ssa_TrustModelIntermediateCert_ext_db6a6327: start-on-event=CertificateElementGetCount, operation=KeyMCertificateElement_Ssa_TrustModelIntermediateCert_ext_pkiRole_003.CertificateElementGetCount
        OpEventCertificateElementGetCount_CertificateElementGetCount_KeyMCertificateElement_Ssa_TrustModelEcuPeerCert_SigAlgoId_006: start-on-event=CertificateElementGetCount, operation=KeyMCertificateElement_Ssa_TrustModelEcuPeerCert_SigAlgoId_006.CertificateElementGetCount
        OpEventCertificateElementGetCount_CertificateElementGetCount_KeyMCertificateElement_Ssa_TrustModelEcuPeerCert_ext_subKeyId_006: start-on-event=CertificateElementGetCount, operation=KeyMCertificateElement_Ssa_TrustModelEcuPeerCert_ext_subKeyId_006.CertificateElementGetCount
        OpEventCertificateElementGetCount_CertificateElementGetCount_KeyMCertificateElement_Ssa_TrustModelEcuCert_subject_005: start-on-event=CertificateElementGetCount, operation=KeyMCertificateElement_Ssa_TrustModelEcuCert_subject_005.CertificateElementGetCount
        OpEventCertificateElementGetCount_CertificateElementGetCount_KeyMCertificateElement_Ssa_TrustModelEcuPeerCert_ext_specialEcu_006: start-on-event=CertificateElementGetCount, operation=KeyMCertificateElement_Ssa_TrustModelEcuPeerCert_ext_specialEcu_006.CertificateElementGetCount
        OpEventCertificateElementGetCount_CertificateElementGetCount_KeyMCertificateElement_Ssa_TrustModelEcuCsr_SubjectPublicK_ac1d7e5b: start-on-event=CertificateElementGetCount, operation=KeyMCertificateElement_Ssa_TrustModelEcuCsr_SubjectPublicKeyInfoAlgo_008.CertificateElementGetCount
        OpEventCertificateElementGetCount_CertificateElementGetCount_KeyMCertificateElement_Ssa_TrustModelIntermediatePeerCert_7c1a255c: start-on-event=CertificateElementGetCount, operation=KeyMCertificateElement_Ssa_TrustModelIntermediatePeerCert_SubjectPublicKeyInfoKey_007.CertificateElementGetCount
        OpEventCertificateElementGetCount_CertificateElementGetCount_KeyMCertificateElement_Ssa_TrustModelEcuCert_SubjectPublic_a6a73c2d: start-on-event=CertificateElementGetCount, operation=KeyMCertificateElement_Ssa_TrustModelEcuCert_SubjectPublicKeyInfoAlgo_005.CertificateElementGetCount
        OpEventCertificateElementGetCount_CertificateElementGetCount_KeyMCertificateElement_Ssa_TrustModelIntermediateCert_subject_003: start-on-event=CertificateElementGetCount, operation=KeyMCertificateElement_Ssa_TrustModelIntermediateCert_subject_003.CertificateElementGetCount
        OpEventCertificateElementGetCount_CertificateElementGetCount_KeyMCertificateElement_Ssa_TrustModelEcuCsr_ext_keyUsage_008: start-on-event=CertificateElementGetCount, operation=KeyMCertificateElement_Ssa_TrustModelEcuCsr_ext_keyUsage_008.CertificateElementGetCount
        OpEventCertificateElementGetCount_CertificateElementGetCount_KeyMCertificateElement_Ssa_TrustModelBackendCert_SubjectPu_69e03499: start-on-event=CertificateElementGetCount, operation=KeyMCertificateElement_Ssa_TrustModelBackendCert_SubjectPublicKeyInfoAlgo_002.CertificateElementGetCount
        OpEventCertificateElementGetCount_CertificateElementGetCount_KeyMCertificateElement_Ssa_TrustModelBackendCert_SerialNo_002: start-on-event=CertificateElementGetCount, operation=KeyMCertificateElement_Ssa_TrustModelBackendCert_SerialNo_002.CertificateElementGetCount
        OpEventCertificateElementGetCount_CertificateElementGetCount_KeyMCertificateElement_Ssa_TrustModelBackendCert_ext_pkiRole_002: start-on-event=CertificateElementGetCount, operation=KeyMCertificateElement_Ssa_TrustModelBackendCert_ext_pkiRole_002.CertificateElementGetCount
        OpEventCertificateElementGetCount_CertificateElementGetCount_KeyMCertificateElement_Ssa_TrustModelEcuPeerCert_SubjectPu_da537dcb: start-on-event=CertificateElementGetCount, operation=KeyMCertificateElement_Ssa_TrustModelEcuPeerCert_SubjectPublicKeyInfoKey_006.CertificateElementGetCount
        OpEventCertificateElementGetCount_CertificateElementGetCount_KeyMCertificateElement_Ssa_TrustModelEcuCert_ext_keyUsage_005: start-on-event=CertificateElementGetCount, operation=KeyMCertificateElement_Ssa_TrustModelEcuCert_ext_keyUsage_005.CertificateElementGetCount
        OpEventCertificateElementGetCount_CertificateElementGetCount_KeyMCertificateElement_Ssa_TrustModelIntermediatePeerCert_45948e79: start-on-event=CertificateElementGetCount, operation=KeyMCertificateElement_Ssa_TrustModelIntermediatePeerCert_signatureAlgorithm_007.CertificateElementGetCount
        OpEventCertificateElementGetCount_CertificateElementGetCount_KeyMCertificateElement_Ssa_TrustModelBackendPeerCert_ext_p_fe996512: start-on-event=CertificateElementGetCount, operation=KeyMCertificateElement_Ssa_TrustModelBackendPeerCert_ext_pkiRole_004.CertificateElementGetCount
        OpEventCertificateElementGetCount_CertificateElementGetCount_KeyMCertificateElement_Ssa_TrustModelEcuCsr_validityNotBefore_008: start-on-event=CertificateElementGetCount, operation=KeyMCertificateElement_Ssa_TrustModelEcuCsr_validityNotBefore_008.CertificateElementGetCount
        OpEventCertificateElementGetCount_CertificateElementGetCount_KeyMCertificateElement_Ssa_TrustModelEcuCert_Version_005: start-on-event=CertificateElementGetCount, operation=KeyMCertificateElement_Ssa_TrustModelEcuCert_Version_005.CertificateElementGetCount
        OpEventCertificateElementGetCount_CertificateElementGetCount_KeyMCertificateElement_Ssa_TrustModelEcuCsr_ext_extKeyUsag_827af557: start-on-event=CertificateElementGetCount, operation=KeyMCertificateElement_Ssa_TrustModelEcuCsr_ext_extKeyUsage_oid1_007.CertificateElementGetCount
        OpEventCertificateElementGetCount_CertificateElementGetCount_KeyMCertificateElement_Ssa_TrustModelBackendCert_Version_002: start-on-event=CertificateElementGetCount, operation=KeyMCertificateElement_Ssa_TrustModelBackendCert_Version_002.CertificateElementGetCount
        OpEventCertificateElementGetCount_CertificateElementGetCount_KeyMCertificateElement_Ssa_TrustModelEcuCsr_subject_008: start-on-event=CertificateElementGetCount, operation=KeyMCertificateElement_Ssa_TrustModelEcuCsr_subject_008.CertificateElementGetCount
        OpEventCertificateElementGetCount_CertificateElementGetCount_KeyMCertificateElement_Ssa_TrustModelEcuCsr_ext_extKeyUsag_f8baa637: start-on-event=CertificateElementGetCount, operation=KeyMCertificateElement_Ssa_TrustModelEcuCsr_ext_extKeyUsage_oid3_007.CertificateElementGetCount
        OpEventCertificateElementGetCount_CertificateElementGetCount_KeyMCertificateElement_Ssa_TrustModelIntermediateCert_ext_00c22f58: start-on-event=CertificateElementGetCount, operation=KeyMCertificateElement_Ssa_TrustModelIntermediateCert_ext_keyUsage_003.CertificateElementGetCount
        OpEventCertificateElementGetCount_CertificateElementGetCount_KeyMCertificateElement_Ssa_TrustModelEcuCert_SigAlgoId_005: start-on-event=CertificateElementGetCount, operation=KeyMCertificateElement_Ssa_TrustModelEcuCert_SigAlgoId_005.CertificateElementGetCount
        OpEventCertificateElementGetCount_CertificateElementGetCount_KeyMCertificateElement_Ssa_TrustModelEcuCsr_signatureValue_008: start-on-event=CertificateElementGetCount, operation=KeyMCertificateElement_Ssa_TrustModelEcuCsr_signatureValue_008.CertificateElementGetCount
        OpEventCertificateElementGetCount_CertificateElementGetCount_KeyMCertificateElement_Ssa_TrustModelBackendPeerCert_signa_b4413e59: start-on-event=CertificateElementGetCount, operation=KeyMCertificateElement_Ssa_TrustModelBackendPeerCert_signatureValue_004.CertificateElementGetCount
        OpEventCertificateElementGetCount_CertificateElementGetCount_KeyMCertificateElement_Ssa_TrustModelEcuPeerCert_Version_006: start-on-event=CertificateElementGetCount, operation=KeyMCertificateElement_Ssa_TrustModelEcuPeerCert_Version_006.CertificateElementGetCount
        OpEventCertificateElementGetCount_CertificateElementGetCount_KeyMCertificateElement_Ssa_TrustModelIntermediatePeerCert_f6d4d5f7: start-on-event=CertificateElementGetCount, operation=KeyMCertificateElement_Ssa_TrustModelIntermediatePeerCert_ext_authKeyId_007.CertificateElementGetCount
        OpEventCertificateElementGetCount_CertificateElementGetCount_KeyMCertificateElement_Ssa_TrustModelIntermediateCert_ext_a00929c8: start-on-event=CertificateElementGetCount, operation=KeyMCertificateElement_Ssa_TrustModelIntermediateCert_ext_authKeyId_003.CertificateElementGetCount
        OpEventCertificateElementGetCount_CertificateElementGetCount_KeyMCertificateElement_Ssa_TrustModelIntermediatePeerCert_91de2aae: start-on-event=CertificateElementGetCount, operation=KeyMCertificateElement_Ssa_TrustModelIntermediatePeerCert_Version_007.CertificateElementGetCount
        OpEventCertificateElementGetCount_CertificateElementGetCount_KeyMCertificateElement_Ssa_TrustModelBackendPeerCert_valid_0a10d79f: start-on-event=CertificateElementGetCount, operation=KeyMCertificateElement_Ssa_TrustModelBackendPeerCert_validityNotAfter_004.CertificateElementGetCount
        OpEventCertificateElementGetCount_CertificateElementGetCount_KeyMCertificateElement_Ssa_TrustModelEcuCsr_Issuer_008: start-on-event=CertificateElementGetCount, operation=KeyMCertificateElement_Ssa_TrustModelEcuCsr_Issuer_008.CertificateElementGetCount
        OpEventCertificateElementGetCount_CertificateElementGetCount_KeyMCertificateElement_Ssa_TrustModelEcuCert_ext_uniqueECUID_005: start-on-event=CertificateElementGetCount, operation=KeyMCertificateElement_Ssa_TrustModelEcuCert_ext_uniqueECUID_005.CertificateElementGetCount
        OpEventCertificateElementGetCount_CertificateElementGetCount_KeyMCertificateElement_Ssa_TrustModelEcuCsr_SigAlgoId_008: start-on-event=CertificateElementGetCount, operation=KeyMCertificateElement_Ssa_TrustModelEcuCsr_SigAlgoId_008.CertificateElementGetCount
        OpEventCertificateElementGetCount_CertificateElementGetCount_KeyMCertificateElement_Ssa_TrustModelEcuPeerCert_SubjectPu_b86ef0f4: start-on-event=CertificateElementGetCount, operation=KeyMCertificateElement_Ssa_TrustModelEcuPeerCert_SubjectPublicKeyInfoAlgo_006.CertificateElementGetCount
        OpEventCertificateElementGetCount_CertificateElementGetCount_KeyMCertificateElement_Ssa_TrustModelEcuPeerCert_signature_6e18786a: start-on-event=CertificateElementGetCount, operation=KeyMCertificateElement_Ssa_TrustModelEcuPeerCert_signatureAlgorithm_006.CertificateElementGetCount
        OpEventCertificateElementGetCount_CertificateElementGetCount_KeyMCertificateElement_Ssa_TrustModelEcuCert_SubjectPublic_8b649de0: start-on-event=CertificateElementGetCount, operation=KeyMCertificateElement_Ssa_TrustModelEcuCert_SubjectPublicKeyInfoKey_005.CertificateElementGetCount
        OpEventCertificateElementGetCount_CertificateElementGetCount_KeyMCertificateElement_Ssa_TrustModelEcuCsr_ext_uniqueECUID_007: start-on-event=CertificateElementGetCount, operation=KeyMCertificateElement_Ssa_TrustModelEcuCsr_ext_uniqueECUID_007.CertificateElementGetCount
        OpEventCertificateElementGetCount_CertificateElementGetCount_KeyMCertificateElement_Ssa_TrustModelIntermediatePeerCert_4d64534a: start-on-event=CertificateElementGetCount, operation=KeyMCertificateElement_Ssa_TrustModelIntermediatePeerCert_validityNotBefore_007.CertificateElementGetCount
        OpEventCertificateElementGetCount_CertificateElementGetCount_KeyMCertificateElement_Ssa_TrustModelEcuCert_validityNotAfter_005: start-on-event=CertificateElementGetCount, operation=KeyMCertificateElement_Ssa_TrustModelEcuCert_validityNotAfter_005.CertificateElementGetCount
        OpEventCertificateElementGetCount_CertificateElementGetCount_KeyMCertificateElement_Ssa_TrustModelIntermediatePeerCert_278ca061: start-on-event=CertificateElementGetCount, operation=KeyMCertificateElement_Ssa_TrustModelIntermediatePeerCert_SigAlgoId_007.CertificateElementGetCount
        OpEventSetCertificate_Ssa_TrustModelEcuCert_SetCertificate_KeyMCertificate_Ssa_TrustModelEcuCert: start-on-event=SetCertificate_Ssa_TrustModelEcuCert, operation=KeyMCertificate_Ssa_TrustModelEcuCert.SetCertificate
        OpEventGetCertificate_Ssa_TrustModelEcuCert_GetCertificate_KeyMCertificate_Ssa_TrustModelEcuCert: start-on-event=GetCertificate_Ssa_TrustModelEcuCert, operation=KeyMCertificate_Ssa_TrustModelEcuCert.GetCertificate
        OpEventCertGetStatus_GetStatus_KeyMCertificate_Ssa_TrustModelBackendCert: start-on-event=CertGetStatus, operation=KeyMCertificate_Ssa_TrustModelBackendCert.GetStatus
        OpEventCertGetStatus_GetStatus_KeyMCertificate_Ssa_TrustModelEcuCert: start-on-event=CertGetStatus, operation=KeyMCertificate_Ssa_TrustModelEcuCert.GetStatus
        OpEventCertGetStatus_GetStatus_KeyMCertificate_Ssa_TrustModelBackendPeerCert: start-on-event=CertGetStatus, operation=KeyMCertificate_Ssa_TrustModelBackendPeerCert.GetStatus
        OpEventCertGetStatus_GetStatus_KeyMCertificate_Ssa_TrustModelEcuCsr: start-on-event=CertGetStatus, operation=KeyMCertificate_Ssa_TrustModelEcuCsr.GetStatus
        OpEventCertGetStatus_GetStatus_KeyMCertificate_Ssa_TrustModelEcuPeerCert: start-on-event=CertGetStatus, operation=KeyMCertificate_Ssa_TrustModelEcuPeerCert.GetStatus
        OpEventCertGetStatus_GetStatus_KeyMCertificate_Ssa_TrustModelIntermediateCert: start-on-event=CertGetStatus, operation=KeyMCertificate_Ssa_TrustModelIntermediateCert.GetStatus
        OpEventCertGetStatus_GetStatus_KeyMCertificate_Ssa_TrustModelIntermediatePeerCert: start-on-event=CertGetStatus, operation=KeyMCertificate_Ssa_TrustModelIntermediatePeerCert.GetStatus
        OpEventCsrElementSet_CsrElementSet_KeyMCertificateExtended_Ssa_TrustModelBackendCert: start-on-event=CsrElementSet, operation=KeyMCertificateExtended_Ssa_TrustModelBackendCert.CsrElementSet
        OpEventCsrElementSet_CsrElementSet_KeyMCertificateExtended_Ssa_TrustModelEcuCsr: start-on-event=CsrElementSet, operation=KeyMCertificateExtended_Ssa_TrustModelEcuCsr.CsrElementSet
        OpEventCsrElementSet_CsrElementSet_KeyMCertificateExtended_Ssa_TrustModelIntermediatePeerCert: start-on-event=CsrElementSet, operation=KeyMCertificateExtended_Ssa_TrustModelIntermediatePeerCert.CsrElementSet
        OpEventCsrElementSet_CsrElementSet_KeyMCertificateExtended_Ssa_TrustModelBackendPeerCert: start-on-event=CsrElementSet, operation=KeyMCertificateExtended_Ssa_TrustModelBackendPeerCert.CsrElementSet
        OpEventCsrElementSet_CsrElementSet_KeyMCertificateExtended_Ssa_TrustModelIntermediateCert: start-on-event=CsrElementSet, operation=KeyMCertificateExtended_Ssa_TrustModelIntermediateCert.CsrElementSet
        OpEventCsrElementSet_CsrElementSet_KeyMCertificateExtended_Ssa_TrustModelEcuPeerCert: start-on-event=CsrElementSet, operation=KeyMCertificateExtended_Ssa_TrustModelEcuPeerCert.CsrElementSet
        OpEventCsrElementSet_CsrElementSet_KeyMCertificateExtended_Ssa_TrustModelEcuCert: start-on-event=CsrElementSet, operation=KeyMCertificateExtended_Ssa_TrustModelEcuCert.CsrElementSet
        OpEventVerifyCertificate_VerifyCertificate_KeyMCertificate_Ssa_TrustModelIntermediateCert: start-on-event=VerifyCertificate, operation=KeyMCertificate_Ssa_TrustModelIntermediateCert.VerifyCertificate
        OpEventVerifyCertificate_VerifyCertificate_KeyMCertificate_Ssa_TrustModelIntermediatePeerCert: start-on-event=VerifyCertificate, operation=KeyMCertificate_Ssa_TrustModelIntermediatePeerCert.VerifyCertificate
        OpEventVerifyCertificate_VerifyCertificate_KeyMCertificate_Ssa_TrustModelEcuCert: start-on-event=VerifyCertificate, operation=KeyMCertificate_Ssa_TrustModelEcuCert.VerifyCertificate
        OpEventVerifyCertificate_VerifyCertificate_KeyMCertificate_Ssa_TrustModelBackendPeerCert: start-on-event=VerifyCertificate, operation=KeyMCertificate_Ssa_TrustModelBackendPeerCert.VerifyCertificate
        OpEventVerifyCertificate_VerifyCertificate_KeyMCertificate_Ssa_TrustModelEcuPeerCert: start-on-event=VerifyCertificate, operation=KeyMCertificate_Ssa_TrustModelEcuPeerCert.VerifyCertificate
        OpEventVerifyCertificate_VerifyCertificate_KeyMCertificate_Ssa_TrustModelBackendCert: start-on-event=VerifyCertificate, operation=KeyMCertificate_Ssa_TrustModelBackendCert.VerifyCertificate
        OpEventVerifyCertificate_VerifyCertificate_KeyMCertificate_Ssa_TrustModelEcuCsr: start-on-event=VerifyCertificate, operation=KeyMCertificate_Ssa_TrustModelEcuCsr.VerifyCertificate
        OpEventSetCertificate_Ssa_TrustModelIntermediateCert_SetCertificate_KeyMCertificate_Ssa_TrustModelIntermediateCert: start-on-event=SetCertificate_Ssa_TrustModelIntermediateCert, operation=KeyMCertificate_Ssa_TrustModelIntermediateCert.SetCertificate
        OpEventSetCertificate_Ssa_TrustModelEcuCsr_SetCertificate_KeyMCertificate_Ssa_TrustModelEcuCsr: start-on-event=SetCertificate_Ssa_TrustModelEcuCsr, operation=KeyMCertificate_Ssa_TrustModelEcuCsr.SetCertificate
        OpEventServiceCertificateByIdRteAdpt_ServiceCertificate_KeyMCertificateExtended_Ssa_TrustModelEcuPeerCert: start-on-event=ServiceCertificateByIdRteAdpt, operation=KeyMCertificateExtended_Ssa_TrustModelEcuPeerCert.ServiceCertificate
        OpEventServiceCertificateByIdRteAdpt_ServiceCertificate_KeyMCertificateExtended_Ssa_TrustModelIntermediatePeerCert: start-on-event=ServiceCertificateByIdRteAdpt, operation=KeyMCertificateExtended_Ssa_TrustModelIntermediatePeerCert.ServiceCertificate
        OpEventServiceCertificateByIdRteAdpt_ServiceCertificate_KeyMCertificateExtended_Ssa_TrustModelEcuCsr: start-on-event=ServiceCertificateByIdRteAdpt, operation=KeyMCertificateExtended_Ssa_TrustModelEcuCsr.ServiceCertificate
        OpEventServiceCertificateByIdRteAdpt_ServiceCertificate_KeyMCertificateExtended_Ssa_TrustModelBackendCert: start-on-event=ServiceCertificateByIdRteAdpt, operation=KeyMCertificateExtended_Ssa_TrustModelBackendCert.ServiceCertificate
        OpEventServiceCertificateByIdRteAdpt_ServiceCertificate_KeyMCertificateExtended_Ssa_TrustModelIntermediateCert: start-on-event=ServiceCertificateByIdRteAdpt, operation=KeyMCertificateExtended_Ssa_TrustModelIntermediateCert.ServiceCertificate
        OpEventServiceCertificateByIdRteAdpt_ServiceCertificate_KeyMCertificateExtended_Ssa_TrustModelEcuCert: start-on-event=ServiceCertificateByIdRteAdpt, operation=KeyMCertificateExtended_Ssa_TrustModelEcuCert.ServiceCertificate
        OpEventServiceCertificateByIdRteAdpt_ServiceCertificate_KeyMCertificateExtended_Ssa_TrustModelBackendPeerCert: start-on-event=ServiceCertificateByIdRteAdpt, operation=KeyMCertificateExtended_Ssa_TrustModelBackendPeerCert.ServiceCertificate
        OpEventGetCertificate_Ssa_TrustModelEcuCsr_GetCertificate_KeyMCertificate_Ssa_TrustModelEcuCsr: start-on-event=GetCertificate_Ssa_TrustModelEcuCsr, operation=KeyMCertificate_Ssa_TrustModelEcuCsr.GetCertificate
        OpEventSetCertificate_Ssa_TrustModelEcuPeerCert_SetCertificate_KeyMCertificate_Ssa_TrustModelEcuPeerCert: start-on-event=SetCertificate_Ssa_TrustModelEcuPeerCert, operation=KeyMCertificate_Ssa_TrustModelEcuPeerCert.SetCertificate
        OpEventGetCertificate_Ssa_TrustModelIntermediateCert_GetCertificate_KeyMCertificate_Ssa_TrustModelIntermediateCert: start-on-event=GetCertificate_Ssa_TrustModelIntermediateCert, operation=KeyMCertificate_Ssa_TrustModelIntermediateCert.GetCertificate
        OpEventSetCertificate_Ssa_TrustModelBackendPeerCert_SetCertificate_KeyMCertificate_Ssa_TrustModelBackendPeerCert: start-on-event=SetCertificate_Ssa_TrustModelBackendPeerCert, operation=KeyMCertificate_Ssa_TrustModelBackendPeerCert.SetCertificate
        OpEventGetCertificate_Ssa_TrustModelEcuPeerCert_GetCertificate_KeyMCertificate_Ssa_TrustModelEcuPeerCert: start-on-event=GetCertificate_Ssa_TrustModelEcuPeerCert, operation=KeyMCertificate_Ssa_TrustModelEcuPeerCert.GetCertificate
        OpEventSetCertificate_Ssa_TrustModelBackendCert_SetCertificate_KeyMCertificate_Ssa_TrustModelBackendCert: start-on-event=SetCertificate_Ssa_TrustModelBackendCert, operation=KeyMCertificate_Ssa_TrustModelBackendCert.SetCertificate
        OpEventSetCertificate_Ssa_TrustModelIntermediatePeerCert_SetCertificate_KeyMCertificate_Ssa_TrustModelIntermediatePeerCert: start-on-event=SetCertificate_Ssa_TrustModelIntermediatePeerCert, operation=KeyMCertificate_Ssa_TrustModelIntermediatePeerCert.SetCertificate
        OpEventGetCertificate_Ssa_TrustModelBackendPeerCert_GetCertificate_KeyMCertificate_Ssa_TrustModelBackendPeerCert: start-on-event=GetCertificate_Ssa_TrustModelBackendPeerCert, operation=KeyMCertificate_Ssa_TrustModelBackendPeerCert.GetCertificate
        OpEventGetCertificate_Ssa_TrustModelIntermediatePeerCert_GetCertificate_KeyMCertificate_Ssa_TrustModelIntermediatePeerCert: start-on-event=GetCertificate_Ssa_TrustModelIntermediatePeerCert, operation=KeyMCertificate_Ssa_TrustModelIntermediatePeerCert.GetCertificate
        OpEventCertificateElementGetCount_CertificateElementGetCount_KeyMCertificateElement_Ssa_TrustModelRootCert_ext_basicConstraints: start-on-event=CertificateElementGetCount, operation=KeyMCertificateElement_Ssa_TrustModelRootCert_ext_basicConstraints.CertificateElementGetCount
        OpEventCertificateElementGetCount_CertificateElementGetCount_KeyMCertificateElement_Ssa_TrustModelRootCert_signatureValue: start-on-event=CertificateElementGetCount, operation=KeyMCertificateElement_Ssa_TrustModelRootCert_signatureValue.CertificateElementGetCount
        OpEventCertificateElementGetCount_CertificateElementGetCount_KeyMCertificateElement_Ssa_TrustModelRootCert_SigAlgoId: start-on-event=CertificateElementGetCount, operation=KeyMCertificateElement_Ssa_TrustModelRootCert_SigAlgoId.CertificateElementGetCount
        OpEventCertificateElementGetCount_CertificateElementGetCount_KeyMCertificateElement_Ssa_TrustModelRootCert_Issuer: start-on-event=CertificateElementGetCount, operation=KeyMCertificateElement_Ssa_TrustModelRootCert_Issuer.CertificateElementGetCount
        OpEventCertificateElementGetCount_CertificateElementGetCount_KeyMCertificateElement_Ssa_TrustModelRootCert_SerialNo: start-on-event=CertificateElementGetCount, operation=KeyMCertificateElement_Ssa_TrustModelRootCert_SerialNo.CertificateElementGetCount
        OpEventCertificateElementGetCount_CertificateElementGetCount_KeyMCertificateElement_Ssa_TrustModelRootCert_validityNotAfter: start-on-event=CertificateElementGetCount, operation=KeyMCertificateElement_Ssa_TrustModelRootCert_validityNotAfter.CertificateElementGetCount
        OpEventCertificateElementGetCount_CertificateElementGetCount_KeyMCertificateElement_Ssa_TrustModelRootCert_ext_keyUsage: start-on-event=CertificateElementGetCount, operation=KeyMCertificateElement_Ssa_TrustModelRootCert_ext_keyUsage.CertificateElementGetCount
        OpEventCertificateElementGetCount_CertificateElementGetCount_KeyMCertificateElement_Ssa_TrustModelRootCert_subject: start-on-event=CertificateElementGetCount, operation=KeyMCertificateElement_Ssa_TrustModelRootCert_subject.CertificateElementGetCount
        OpEventCertificateElementGetCount_CertificateElementGetCount_KeyMCertificateElement_Ssa_TrustModelRootCert_SubjectPubli_43b69680: start-on-event=CertificateElementGetCount, operation=KeyMCertificateElement_Ssa_TrustModelRootCert_SubjectPublicKeyInfoKey.CertificateElementGetCount
        OpEventCertificateElementGetCount_CertificateElementGetCount_KeyMCertificateElement_Ssa_TrustModelRootCert_Version: start-on-event=CertificateElementGetCount, operation=KeyMCertificateElement_Ssa_TrustModelRootCert_Version.CertificateElementGetCount
        OpEventCertificateElementGetCount_CertificateElementGetCount_KeyMCertificateElement_Ssa_TrustModelRootCert_signatureAlgorithm: start-on-event=CertificateElementGetCount, operation=KeyMCertificateElement_Ssa_TrustModelRootCert_signatureAlgorithm.CertificateElementGetCount
        OpEventCertificateElementGetCount_CertificateElementGetCount_KeyMCertificateElement_Ssa_TrustModelRootCert_SubjectPubli_56d942c6: start-on-event=CertificateElementGetCount, operation=KeyMCertificateElement_Ssa_TrustModelRootCert_SubjectPublicKeyInfoAlgo.CertificateElementGetCount
        OpEventCertificateElementGetCount_CertificateElementGetCount_KeyMCertificateElement_Ssa_TrustModelRootCert_ext_pkiRole: start-on-event=CertificateElementGetCount, operation=KeyMCertificateElement_Ssa_TrustModelRootCert_ext_pkiRole.CertificateElementGetCount
        OpEventCertificateElementGetCount_CertificateElementGetCount_KeyMCertificateElement_Ssa_TrustModelRootCert_ext_subKeyId: start-on-event=CertificateElementGetCount, operation=KeyMCertificateElement_Ssa_TrustModelRootCert_ext_subKeyId.CertificateElementGetCount
        OpEventCertificateElementGetCount_CertificateElementGetCount_KeyMCertificateElement_Ssa_TrustModelRootCert_validityNotBefore: start-on-event=CertificateElementGetCount, operation=KeyMCertificateElement_Ssa_TrustModelRootCert_validityNotBefore.CertificateElementGetCount
        OpEventServiceCertificateByIdRteAdpt_ServiceCertificate_KeyMCertificateExtended_Ssa_TrustModelRootCert: start-on-event=ServiceCertificateByIdRteAdpt, operation=KeyMCertificateExtended_Ssa_TrustModelRootCert.ServiceCertificate
        OpEventCertGetStatus_GetStatus_KeyMCertificate_Ssa_TrustModelRootCert: start-on-event=CertGetStatus, operation=KeyMCertificate_Ssa_TrustModelRootCert.GetStatus
        OpEventCsrElementSet_CsrElementSet_KeyMCertificateExtended_Ssa_TrustModelRootCert: start-on-event=CsrElementSet, operation=KeyMCertificateExtended_Ssa_TrustModelRootCert.CsrElementSet
        OpEventVerifyCertificate_VerifyCertificate_KeyMCertificate_Ssa_TrustModelRootCert: start-on-event=VerifyCertificate, operation=KeyMCertificate_Ssa_TrustModelRootCert.VerifyCertificate
        OpEventGetCertificate_Ssa_TrustModelRootCert_GetCertificate_KeyMCertificate_Ssa_TrustModelRootCert: start-on-event=GetCertificate_Ssa_TrustModelRootCert, operation=KeyMCertificate_Ssa_TrustModelRootCert.GetCertificate
        OpEventSetCertificate_Ssa_TrustModelRootCert_SetCertificate_KeyMCertificate_Ssa_TrustModelRootCert: start-on-event=SetCertificate_Ssa_TrustModelRootCert, operation=KeyMCertificate_Ssa_TrustModelRootCert.SetCertificate
        OpEventCertificateElementGetCount_CertificateElementGetCount_KeyMCertificateElement_Ssa_TrustModelEcuCert_ext_pkiRole_006: start-on-event=CertificateElementGetCount, operation=KeyMCertificateElement_Ssa_TrustModelEcuCert_ext_pkiRole_006.CertificateElementGetCount
        OpEventCertificateElementGetCount_CertificateElementGetCount_KeyMCertificateElement_Ssa_TrustModelIntermediatePeerCert_61131085: start-on-event=CertificateElementGetCount, operation=KeyMCertificateElement_Ssa_TrustModelIntermediatePeerCert_ext_pkiRole_005.CertificateElementGetCount
        OpEventCertificateElementGetCount_CertificateElementGetCount_KeyMCertificateElement_Ssa_TrustModelRootCert_ext_authKeyId_009: start-on-event=CertificateElementGetCount, operation=KeyMCertificateElement_Ssa_TrustModelRootCert_ext_authKeyId_009.CertificateElementGetCount
        OpEventCertificateElementGetByIndex_Ssa_TrustModelBackendCert_ext_authKeyId_002_CertificateElementGetByIndex_KeyMCertif_f4e6bab9: start-on-event=CertificateElementGetByIndex_Ssa_TrustModelBackendCert_ext_authKeyId_002, operation=KeyMCertificateElement_Ssa_TrustModelBackendCert_ext_authKeyId_002.CertificateElementGetByIndex
        OpEventCertificateElementGetByIndex_Ssa_TrustModelBackendCert_Issuer_002_CertificateElementGetByIndex_KeyMCertificateEl_4f0a755f: start-on-event=CertificateElementGetByIndex_Ssa_TrustModelBackendCert_Issuer_002, operation=KeyMCertificateElement_Ssa_TrustModelBackendCert_Issuer_002.CertificateElementGetByIndex
        OpEventCertElementGet_Ssa_TrustModelBackendCert_ext_subKeyId_002_CertificateElementGet_KeyMCertificateElement_Ssa_Trust_ba13aece: start-on-event=CertElementGet_Ssa_TrustModelBackendCert_ext_subKeyId_002, operation=KeyMCertificateElement_Ssa_TrustModelBackendCert_ext_subKeyId_002.CertificateElementGet
        OpEventCertificateElementGetByIndex_Ssa_TrustModelEcuPeerCert_ext_authKeyId_006_CertificateElementGetByIndex_KeyMCertif_1082bcd9: start-on-event=CertificateElementGetByIndex_Ssa_TrustModelEcuPeerCert_ext_authKeyId_006, operation=KeyMCertificateElement_Ssa_TrustModelEcuPeerCert_ext_authKeyId_006.CertificateElementGetByIndex
        OpEventCertificateElementGetByIndex_Ssa_TrustModelIntermediateCert_SubjectPublicKeyInfoAlgo_003_CertificateElementGetBy_f6dac145: start-on-event=CertificateElementGetByIndex_Ssa_TrustModelIntermediateCert_SubjectPublicKeyInfoAlgo_003, operation=KeyMCertificateElement_Ssa_TrustModelIntermediateCert_SubjectPublicKeyInfoAlgo_003.CertificateElementGetByIndex
        OpEventCertificateElementGetByIndex_Ssa_TrustModelBackendCert_Version_002_CertificateElementGetByIndex_KeyMCertificateE_039944b2: start-on-event=CertificateElementGetByIndex_Ssa_TrustModelBackendCert_Version_002, operation=KeyMCertificateElement_Ssa_TrustModelBackendCert_Version_002.CertificateElementGetByIndex
        OpEventCertElementGet_Ssa_TrustModelRootCert_ext_pkiRole_CertificateElementGet_KeyMCertificateElement_Ssa_TrustModelRoo_3ff8c5d0: start-on-event=CertElementGet_Ssa_TrustModelRootCert_ext_pkiRole, operation=KeyMCertificateElement_Ssa_TrustModelRootCert_ext_pkiRole.CertificateElementGet
        OpEventCertificateElementGetByIndex_Ssa_TrustModelRootCert_Issuer_CertificateElementGetByIndex_KeyMCertificateElement_S_909ae8c3: start-on-event=CertificateElementGetByIndex_Ssa_TrustModelRootCert_Issuer, operation=KeyMCertificateElement_Ssa_TrustModelRootCert_Issuer.CertificateElementGetByIndex
        OpEventCertificateElementGetByIndex_Ssa_TrustModelIntermediatePeerCert_Version_007_CertificateElementGetByIndex_KeyMCer_20f6fac2: start-on-event=CertificateElementGetByIndex_Ssa_TrustModelIntermediatePeerCert_Version_007, operation=KeyMCertificateElement_Ssa_TrustModelIntermediatePeerCert_Version_007.CertificateElementGetByIndex
        OpEventCertElementGet_Ssa_TrustModelBackendCert_ext_authKeyId_002_CertificateElementGet_KeyMCertificateElement_Ssa_Trus_44f561f7: start-on-event=CertElementGet_Ssa_TrustModelBackendCert_ext_authKeyId_002, operation=KeyMCertificateElement_Ssa_TrustModelBackendCert_ext_authKeyId_002.CertificateElementGet
        OpEventCertElementGet_Ssa_TrustModelEcuPeerCert_validityNotBefore_006_CertificateElementGet_KeyMCertificateElement_Ssa_3b1b4dfd: start-on-event=CertElementGet_Ssa_TrustModelEcuPeerCert_validityNotBefore_006, operation=KeyMCertificateElement_Ssa_TrustModelEcuPeerCert_validityNotBefore_006.CertificateElementGet
        OpEventCertElementGet_Ssa_TrustModelBackendPeerCert_subject_004_CertificateElementGet_KeyMCertificateElement_Ssa_TrustM_18a9f044: start-on-event=CertElementGet_Ssa_TrustModelBackendPeerCert_subject_004, operation=KeyMCertificateElement_Ssa_TrustModelBackendPeerCert_subject_004.CertificateElementGet
        OpEventCertificateElementGetByIndex_Ssa_TrustModelEcuCert_ext_subKeyId_005_CertificateElementGetByIndex_KeyMCertificate_f7eb8987: start-on-event=CertificateElementGetByIndex_Ssa_TrustModelEcuCert_ext_subKeyId_005, operation=KeyMCertificateElement_Ssa_TrustModelEcuCert_ext_subKeyId_005.CertificateElementGetByIndex
        OpEventCertificateElementGetByIndex_Ssa_TrustModelRootCert_ext_keyUsage_CertificateElementGetByIndex_KeyMCertificateEle_00edf77d: start-on-event=CertificateElementGetByIndex_Ssa_TrustModelRootCert_ext_keyUsage, operation=KeyMCertificateElement_Ssa_TrustModelRootCert_ext_keyUsage.CertificateElementGetByIndex
        OpEventCertElementGet_Ssa_TrustModelEcuPeerCert_SigAlgoId_006_CertificateElementGet_KeyMCertificateElement_Ssa_TrustMod_8f6b5f9c: start-on-event=CertElementGet_Ssa_TrustModelEcuPeerCert_SigAlgoId_006, operation=KeyMCertificateElement_Ssa_TrustModelEcuPeerCert_SigAlgoId_006.CertificateElementGet
        OpEventCertElementGet_Ssa_TrustModelBackendCert_Issuer_002_CertificateElementGet_KeyMCertificateElement_Ssa_TrustModelB_1ef94229: start-on-event=CertElementGet_Ssa_TrustModelBackendCert_Issuer_002, operation=KeyMCertificateElement_Ssa_TrustModelBackendCert_Issuer_002.CertificateElementGet
        OpEventCertificateElementGetByIndex_Ssa_TrustModelBackendPeerCert_ext_pkiRole_004_CertificateElementGetByIndex_KeyMCert_a17fa174: start-on-event=CertificateElementGetByIndex_Ssa_TrustModelBackendPeerCert_ext_pkiRole_004, operation=KeyMCertificateElement_Ssa_TrustModelBackendPeerCert_ext_pkiRole_004.CertificateElementGetByIndex
        OpEventCertificateElementGetByIndex_Ssa_TrustModelIntermediatePeerCert_SigAlgoId_007_CertificateElementGetByIndex_KeyMC_a108a947: start-on-event=CertificateElementGetByIndex_Ssa_TrustModelIntermediatePeerCert_SigAlgoId_007, operation=KeyMCertificateElement_Ssa_TrustModelIntermediatePeerCert_SigAlgoId_007.CertificateElementGetByIndex
        OpEventCertElementGet_Ssa_TrustModelIntermediateCert_ext_subKeyId_003_CertificateElementGet_KeyMCertificateElement_Ssa_6121e747: start-on-event=CertElementGet_Ssa_TrustModelIntermediateCert_ext_subKeyId_003, operation=KeyMCertificateElement_Ssa_TrustModelIntermediateCert_ext_subKeyId_003.CertificateElementGet
        OpEventCertificateElementGetByIndex_Ssa_TrustModelBackendCert_SigAlgoId_002_CertificateElementGetByIndex_KeyMCertificat_850bb184: start-on-event=CertificateElementGetByIndex_Ssa_TrustModelBackendCert_SigAlgoId_002, operation=KeyMCertificateElement_Ssa_TrustModelBackendCert_SigAlgoId_002.CertificateElementGetByIndex
        OpEventCertificateElementGetByIndex_Ssa_TrustModelEcuCsr_ext_subKeyId_008_CertificateElementGetByIndex_KeyMCertificateE_12d1cb35: start-on-event=CertificateElementGetByIndex_Ssa_TrustModelEcuCsr_ext_subKeyId_008, operation=KeyMCertificateElement_Ssa_TrustModelEcuCsr_ext_subKeyId_008.CertificateElementGetByIndex
        OpEventCertElementGet_Ssa_TrustModelEcuCsr_ext_specialEcu_007_CertificateElementGet_KeyMCertificateElement_Ssa_TrustMod_2ab7d842: start-on-event=CertElementGet_Ssa_TrustModelEcuCsr_ext_specialEcu_007, operation=KeyMCertificateElement_Ssa_TrustModelEcuCsr_ext_specialEcu_007.CertificateElementGet
        OpEventCertElementGet_Ssa_TrustModelEcuCsr_ext_extKeyUsage_007_CertificateElementGet_KeyMCertificateElement_Ssa_TrustMo_12265670: start-on-event=CertElementGet_Ssa_TrustModelEcuCsr_ext_extKeyUsage_007, operation=KeyMCertificateElement_Ssa_TrustModelEcuCsr_ext_extKeyUsage_007.CertificateElementGet
        OpEventCertElementGet_Ssa_TrustModelRootCert_subject_CertificateElementGet_KeyMCertificateElement_Ssa_TrustModelRootCert_subject: start-on-event=CertElementGet_Ssa_TrustModelRootCert_subject, operation=KeyMCertificateElement_Ssa_TrustModelRootCert_subject.CertificateElementGet
        OpEventCertElementGet_Ssa_TrustModelBackendCert_subject_002_CertificateElementGet_KeyMCertificateElement_Ssa_TrustModel_1f75b17e: start-on-event=CertElementGet_Ssa_TrustModelBackendCert_subject_002, operation=KeyMCertificateElement_Ssa_TrustModelBackendCert_subject_002.CertificateElementGet
        OpEventCertElementGet_Ssa_TrustModelEcuCsr_validityNotBefore_008_CertificateElementGet_KeyMCertificateElement_Ssa_Trust_3d3e2ead: start-on-event=CertElementGet_Ssa_TrustModelEcuCsr_validityNotBefore_008, operation=KeyMCertificateElement_Ssa_TrustModelEcuCsr_validityNotBefore_008.CertificateElementGet
        OpEventCertificateElementGetByIndex_Ssa_TrustModelEcuPeerCert_SigAlgoId_006_CertificateElementGetByIndex_KeyMCertificat_2dff6f88: start-on-event=CertificateElementGetByIndex_Ssa_TrustModelEcuPeerCert_SigAlgoId_006, operation=KeyMCertificateElement_Ssa_TrustModelEcuPeerCert_SigAlgoId_006.CertificateElementGetByIndex
        OpEventCertElementGet_Ssa_TrustModelBackendCert_ext_pkiRole_002_CertificateElementGet_KeyMCertificateElement_Ssa_TrustM_8f7d306a: start-on-event=CertElementGet_Ssa_TrustModelBackendCert_ext_pkiRole_002, operation=KeyMCertificateElement_Ssa_TrustModelBackendCert_ext_pkiRole_002.CertificateElementGet
        OpEventCertElementGet_Ssa_TrustModelRootCert_signatureValue_CertificateElementGet_KeyMCertificateElement_Ssa_TrustModel_244b5928: start-on-event=CertElementGet_Ssa_TrustModelRootCert_signatureValue, operation=KeyMCertificateElement_Ssa_TrustModelRootCert_signatureValue.CertificateElementGet
        OpEventCertificateElementGetByIndex_Ssa_TrustModelBackendPeerCert_SerialNo_004_CertificateElementGetByIndex_KeyMCertifi_9fbcebda: start-on-event=CertificateElementGetByIndex_Ssa_TrustModelBackendPeerCert_SerialNo_004, operation=KeyMCertificateElement_Ssa_TrustModelBackendPeerCert_SerialNo_004.CertificateElementGetByIndex
        OpEventCertificateElementGetByIndex_Ssa_TrustModelBackendPeerCert_ext_basicConstraints_004_CertificateElementGetByIndex_5449b4cf: start-on-event=CertificateElementGetByIndex_Ssa_TrustModelBackendPeerCert_ext_basicConstraints_004, operation=KeyMCertificateElement_Ssa_TrustModelBackendPeerCert_ext_basicConstraints_004.CertificateElementGetByIndex
        OpEventCertificateElementGetByIndex_Ssa_TrustModelEcuCsr_SubjectPublicKeyInfoAlgo_008_CertificateElementGetByIndex_KeyM_1c1fc6be: start-on-event=CertificateElementGetByIndex_Ssa_TrustModelEcuCsr_SubjectPublicKeyInfoAlgo_008, operation=KeyMCertificateElement_Ssa_TrustModelEcuCsr_SubjectPublicKeyInfoAlgo_008.CertificateElementGetByIndex
        OpEventCertElementGet_Ssa_TrustModelBackendPeerCert_SerialNo_004_CertificateElementGet_KeyMCertificateElement_Ssa_Trust_befa4711: start-on-event=CertElementGet_Ssa_TrustModelBackendPeerCert_SerialNo_004, operation=KeyMCertificateElement_Ssa_TrustModelBackendPeerCert_SerialNo_004.CertificateElementGet
        OpEventCertificateElementGetByIndex_Ssa_TrustModelRootCert_validityNotAfter_CertificateElementGetByIndex_KeyMCertificat_bedbd438: start-on-event=CertificateElementGetByIndex_Ssa_TrustModelRootCert_validityNotAfter, operation=KeyMCertificateElement_Ssa_TrustModelRootCert_validityNotAfter.CertificateElementGetByIndex
        OpEventCertElementGet_Ssa_TrustModelRootCert_validityNotAfter_CertificateElementGet_KeyMCertificateElement_Ssa_TrustMod_6c287909: start-on-event=CertElementGet_Ssa_TrustModelRootCert_validityNotAfter, operation=KeyMCertificateElement_Ssa_TrustModelRootCert_validityNotAfter.CertificateElementGet
        OpEventCertElementGet_Ssa_TrustModelEcuCert_SubjectPublicKeyInfoAlgo_005_CertificateElementGet_KeyMCertificateElement_S_c82899ae: start-on-event=CertElementGet_Ssa_TrustModelEcuCert_SubjectPublicKeyInfoAlgo_005, operation=KeyMCertificateElement_Ssa_TrustModelEcuCert_SubjectPublicKeyInfoAlgo_005.CertificateElementGet
        OpEventCertificateElementGetByIndex_Ssa_TrustModelEcuPeerCert_ext_keyUsage_006_CertificateElementGetByIndex_KeyMCertifi_2bbad27d: start-on-event=CertificateElementGetByIndex_Ssa_TrustModelEcuPeerCert_ext_keyUsage_006, operation=KeyMCertificateElement_Ssa_TrustModelEcuPeerCert_ext_keyUsage_006.CertificateElementGetByIndex
        OpEventCertElementGet_Ssa_TrustModelIntermediatePeerCert_ext_subKeyId_007_CertificateElementGet_KeyMCertificateElement_6e96c97b: start-on-event=CertElementGet_Ssa_TrustModelIntermediatePeerCert_ext_subKeyId_007, operation=KeyMCertificateElement_Ssa_TrustModelIntermediatePeerCert_ext_subKeyId_007.CertificateElementGet
        OpEventCertElementGet_Ssa_TrustModelEcuPeerCert_SerialNo_006_CertificateElementGet_KeyMCertificateElement_Ssa_TrustMode_28d5235b: start-on-event=CertElementGet_Ssa_TrustModelEcuPeerCert_SerialNo_006, operation=KeyMCertificateElement_Ssa_TrustModelEcuPeerCert_SerialNo_006.CertificateElementGet
        OpEventCertElementGet_Ssa_TrustModelEcuCert_validityNotAfter_005_CertificateElementGet_KeyMCertificateElement_Ssa_Trust_bc0d4fa1: start-on-event=CertElementGet_Ssa_TrustModelEcuCert_validityNotAfter_005, operation=KeyMCertificateElement_Ssa_TrustModelEcuCert_validityNotAfter_005.CertificateElementGet
        OpEventCertificateElementGetByIndex_Ssa_TrustModelEcuCsr_Version_008_CertificateElementGetByIndex_KeyMCertificateElemen_c1287c59: start-on-event=CertificateElementGetByIndex_Ssa_TrustModelEcuCsr_Version_008, operation=KeyMCertificateElement_Ssa_TrustModelEcuCsr_Version_008.CertificateElementGetByIndex
        OpEventCertElementGet_Ssa_TrustModelBackendCert_SigAlgoId_002_CertificateElementGet_KeyMCertificateElement_Ssa_TrustMod_38a4bbe6: start-on-event=CertElementGet_Ssa_TrustModelBackendCert_SigAlgoId_002, operation=KeyMCertificateElement_Ssa_TrustModelBackendCert_SigAlgoId_002.CertificateElementGet
        OpEventCertificateElementGetByIndex_Ssa_TrustModelEcuCsr_ext_specialEcu_007_CertificateElementGetByIndex_KeyMCertificat_379ad74a: start-on-event=CertificateElementGetByIndex_Ssa_TrustModelEcuCsr_ext_specialEcu_007, operation=KeyMCertificateElement_Ssa_TrustModelEcuCsr_ext_specialEcu_007.CertificateElementGetByIndex
        OpEventCertElementGet_Ssa_TrustModelBackendPeerCert_SubjectPublicKeyInfoAlgo_004_CertificateElementGet_KeyMCertificateE_7080f3b8: start-on-event=CertElementGet_Ssa_TrustModelBackendPeerCert_SubjectPublicKeyInfoAlgo_004, operation=KeyMCertificateElement_Ssa_TrustModelBackendPeerCert_SubjectPublicKeyInfoAlgo_004.CertificateElementGet
        OpEventCertElementGet_Ssa_TrustModelEcuCsr_signatureValue_008_CertificateElementGet_KeyMCertificateElement_Ssa_TrustMod_724df85a: start-on-event=CertElementGet_Ssa_TrustModelEcuCsr_signatureValue_008, operation=KeyMCertificateElement_Ssa_TrustModelEcuCsr_signatureValue_008.CertificateElementGet
        OpEventCertificateElementGetByIndex_Ssa_TrustModelEcuCsr_ext_uniqueECUID_007_CertificateElementGetByIndex_KeyMCertifica_f69dc438: start-on-event=CertificateElementGetByIndex_Ssa_TrustModelEcuCsr_ext_uniqueECUID_007, operation=KeyMCertificateElement_Ssa_TrustModelEcuCsr_ext_uniqueECUID_007.CertificateElementGetByIndex
        OpEventCertificateElementGetByIndex_Ssa_TrustModelIntermediateCert_ext_subKeyId_003_CertificateElementGetByIndex_KeyMCe_a5f1b355: start-on-event=CertificateElementGetByIndex_Ssa_TrustModelIntermediateCert_ext_subKeyId_003, operation=KeyMCertificateElement_Ssa_TrustModelIntermediateCert_ext_subKeyId_003.CertificateElementGetByIndex
        OpEventCertElementGet_Ssa_TrustModelIntermediatePeerCert_SerialNo_007_CertificateElementGet_KeyMCertificateElement_Ssa_bbcebf4c: start-on-event=CertElementGet_Ssa_TrustModelIntermediatePeerCert_SerialNo_007, operation=KeyMCertificateElement_Ssa_TrustModelIntermediatePeerCert_SerialNo_007.CertificateElementGet
        OpEventCertificateElementGetByIndex_Ssa_TrustModelEcuCsr_SubjectPublicKeyInfoKey_008_CertificateElementGetByIndex_KeyMC_cb673579: start-on-event=CertificateElementGetByIndex_Ssa_TrustModelEcuCsr_SubjectPublicKeyInfoKey_008, operation=KeyMCertificateElement_Ssa_TrustModelEcuCsr_SubjectPublicKeyInfoKey_008.CertificateElementGetByIndex
        OpEventCertificateElementGetByIndex_Ssa_TrustModelEcuCsr_ext_extKeyUsage_oid1_007_CertificateElementGetByIndex_KeyMCert_1d4611be: start-on-event=CertificateElementGetByIndex_Ssa_TrustModelEcuCsr_ext_extKeyUsage_oid1_007, operation=KeyMCertificateElement_Ssa_TrustModelEcuCsr_ext_extKeyUsage_oid1_007.CertificateElementGetByIndex
        OpEventCertificateElementGetByIndex_Ssa_TrustModelEcuCert_subject_005_CertificateElementGetByIndex_KeyMCertificateEleme_13b3b58c: start-on-event=CertificateElementGetByIndex_Ssa_TrustModelEcuCert_subject_005, operation=KeyMCertificateElement_Ssa_TrustModelEcuCert_subject_005.CertificateElementGetByIndex
        OpEventCertificateElementGetByIndex_Ssa_TrustModelIntermediatePeerCert_SubjectPublicKeyInfoKey_007_CertificateElementGe_7cc43f4b: start-on-event=CertificateElementGetByIndex_Ssa_TrustModelIntermediatePeerCert_SubjectPublicKeyInfoKey_007, operation=KeyMCertificateElement_Ssa_TrustModelIntermediatePeerCert_SubjectPublicKeyInfoKey_007.CertificateElementGetByIndex
        OpEventCertificateElementGetByIndex_Ssa_TrustModelEcuCsr_SerialNo_008_CertificateElementGetByIndex_KeyMCertificateEleme_0ae811db: start-on-event=CertificateElementGetByIndex_Ssa_TrustModelEcuCsr_SerialNo_008, operation=KeyMCertificateElement_Ssa_TrustModelEcuCsr_SerialNo_008.CertificateElementGetByIndex
        OpEventCertificateElementGetByIndex_Ssa_TrustModelEcuPeerCert_SubjectPublicKeyInfoKey_006_CertificateElementGetByIndex_67daaccc: start-on-event=CertificateElementGetByIndex_Ssa_TrustModelEcuPeerCert_SubjectPublicKeyInfoKey_006, operation=KeyMCertificateElement_Ssa_TrustModelEcuPeerCert_SubjectPublicKeyInfoKey_006.CertificateElementGetByIndex
        OpEventCertificateElementGetByIndex_Ssa_TrustModelBackendPeerCert_Issuer_004_CertificateElementGetByIndex_KeyMCertifica_b812d327: start-on-event=CertificateElementGetByIndex_Ssa_TrustModelBackendPeerCert_Issuer_004, operation=KeyMCertificateElement_Ssa_TrustModelBackendPeerCert_Issuer_004.CertificateElementGetByIndex
        OpEventCertificateElementGetByIndex_Ssa_TrustModelRootCert_signatureAlgorithm_CertificateElementGetByIndex_KeyMCertific_9c5469c4: start-on-event=CertificateElementGetByIndex_Ssa_TrustModelRootCert_signatureAlgorithm, operation=KeyMCertificateElement_Ssa_TrustModelRootCert_signatureAlgorithm.CertificateElementGetByIndex
        OpEventCertificateElementGetByIndex_Ssa_TrustModelIntermediatePeerCert_SubjectPublicKeyInfoAlgo_007_CertificateElementG_9d0e454e: start-on-event=CertificateElementGetByIndex_Ssa_TrustModelIntermediatePeerCert_SubjectPublicKeyInfoAlgo_007, operation=KeyMCertificateElement_Ssa_TrustModelIntermediatePeerCert_SubjectPublicKeyInfoAlgo_007.CertificateElementGetByIndex
        OpEventCertElementGet_Ssa_TrustModelBackendPeerCert_validityNotAfter_004_CertificateElementGet_KeyMCertificateElement_S_98bf022b: start-on-event=CertElementGet_Ssa_TrustModelBackendPeerCert_validityNotAfter_004, operation=KeyMCertificateElement_Ssa_TrustModelBackendPeerCert_validityNotAfter_004.CertificateElementGet
        OpEventCertificateElementGetByIndex_Ssa_TrustModelRootCert_ext_authKeyId_009_CertificateElementGetByIndex_KeyMCertifica_4973c111: start-on-event=CertificateElementGetByIndex_Ssa_TrustModelRootCert_ext_authKeyId_009, operation=KeyMCertificateElement_Ssa_TrustModelRootCert_ext_authKeyId_009.CertificateElementGetByIndex
        OpEventCertElementGet_Ssa_TrustModelIntermediateCert_SerialNo_003_CertificateElementGet_KeyMCertificateElement_Ssa_Trus_b5a11aed: start-on-event=CertElementGet_Ssa_TrustModelIntermediateCert_SerialNo_003, operation=KeyMCertificateElement_Ssa_TrustModelIntermediateCert_SerialNo_003.CertificateElementGet
        OpEventCertificateElementGetByIndex_Ssa_TrustModelBackendPeerCert_SubjectPublicKeyInfoAlgo_004_CertificateElementGetByI_0ff02460: start-on-event=CertificateElementGetByIndex_Ssa_TrustModelBackendPeerCert_SubjectPublicKeyInfoAlgo_004, operation=KeyMCertificateElement_Ssa_TrustModelBackendPeerCert_SubjectPublicKeyInfoAlgo_004.CertificateElementGetByIndex
        OpEventCertElementGet_Ssa_TrustModelEcuCert_SubjectPublicKeyInfoKey_005_CertificateElementGet_KeyMCertificateElement_Ss_656b961e: start-on-event=CertElementGet_Ssa_TrustModelEcuCert_SubjectPublicKeyInfoKey_005, operation=KeyMCertificateElement_Ssa_TrustModelEcuCert_SubjectPublicKeyInfoKey_005.CertificateElementGet
        OpEventCertificateElementGetByIndex_Ssa_TrustModelIntermediateCert_SubjectPublicKeyInfoKey_003_CertificateElementGetByI_fe531eac: start-on-event=CertificateElementGetByIndex_Ssa_TrustModelIntermediateCert_SubjectPublicKeyInfoKey_003, operation=KeyMCertificateElement_Ssa_TrustModelIntermediateCert_SubjectPublicKeyInfoKey_003.CertificateElementGetByIndex
        OpEventCertElementGet_Ssa_TrustModelEcuCsr_ext_extKeyUsage_oid1_007_CertificateElementGet_KeyMCertificateElement_Ssa_Tr_8018acb1: start-on-event=CertElementGet_Ssa_TrustModelEcuCsr_ext_extKeyUsage_oid1_007, operation=KeyMCertificateElement_Ssa_TrustModelEcuCsr_ext_extKeyUsage_oid1_007.CertificateElementGet
        OpEventCertElementGet_Ssa_TrustModelBackendPeerCert_ext_pkiRole_004_CertificateElementGet_KeyMCertificateElement_Ssa_Tr_316617f4: start-on-event=CertElementGet_Ssa_TrustModelBackendPeerCert_ext_pkiRole_004, operation=KeyMCertificateElement_Ssa_TrustModelBackendPeerCert_ext_pkiRole_004.CertificateElementGet
        OpEventCertElementGet_Ssa_TrustModelEcuPeerCert_ext_authKeyId_006_CertificateElementGet_KeyMCertificateElement_Ssa_Trus_60cfe6cc: start-on-event=CertElementGet_Ssa_TrustModelEcuPeerCert_ext_authKeyId_006, operation=KeyMCertificateElement_Ssa_TrustModelEcuPeerCert_ext_authKeyId_006.CertificateElementGet
        OpEventCertElementGet_Ssa_TrustModelEcuCsr_Version_008_CertificateElementGet_KeyMCertificateElement_Ssa_TrustModelEcuCs_410ea579: start-on-event=CertElementGet_Ssa_TrustModelEcuCsr_Version_008, operation=KeyMCertificateElement_Ssa_TrustModelEcuCsr_Version_008.CertificateElementGet
        OpEventCertElementGet_Ssa_TrustModelEcuCert_ext_keyUsage_005_CertificateElementGet_KeyMCertificateElement_Ssa_TrustMode_93427bf2: start-on-event=CertElementGet_Ssa_TrustModelEcuCert_ext_keyUsage_005, operation=KeyMCertificateElement_Ssa_TrustModelEcuCert_ext_keyUsage_005.CertificateElementGet
        OpEventCertElementGet_Ssa_TrustModelIntermediateCert_validityNotAfter_003_CertificateElementGet_KeyMCertificateElement_64b056ab: start-on-event=CertElementGet_Ssa_TrustModelIntermediateCert_validityNotAfter_003, operation=KeyMCertificateElement_Ssa_TrustModelIntermediateCert_validityNotAfter_003.CertificateElementGet
        OpEventCertElementGet_Ssa_TrustModelIntermediatePeerCert_validityNotBefore_007_CertificateElementGet_KeyMCertificateEle_e81f7440: start-on-event=CertElementGet_Ssa_TrustModelIntermediatePeerCert_validityNotBefore_007, operation=KeyMCertificateElement_Ssa_TrustModelIntermediatePeerCert_validityNotBefore_007.CertificateElementGet
        OpEventCertificateElementGetByIndex_Ssa_TrustModelBackendCert_SerialNo_002_CertificateElementGetByIndex_KeyMCertificate_e25d1b80: start-on-event=CertificateElementGetByIndex_Ssa_TrustModelBackendCert_SerialNo_002, operation=KeyMCertificateElement_Ssa_TrustModelBackendCert_SerialNo_002.CertificateElementGetByIndex
        OpEventCertificateElementGetByIndex_Ssa_TrustModelEcuPeerCert_ext_subKeyId_006_CertificateElementGetByIndex_KeyMCertifi_8e802a37: start-on-event=CertificateElementGetByIndex_Ssa_TrustModelEcuPeerCert_ext_subKeyId_006, operation=KeyMCertificateElement_Ssa_TrustModelEcuPeerCert_ext_subKeyId_006.CertificateElementGetByIndex
        OpEventCertificateElementGetByIndex_Ssa_TrustModelIntermediateCert_signatureValue_003_CertificateElementGetByIndex_KeyM_3b79b831: start-on-event=CertificateElementGetByIndex_Ssa_TrustModelIntermediateCert_signatureValue_003, operation=KeyMCertificateElement_Ssa_TrustModelIntermediateCert_signatureValue_003.CertificateElementGetByIndex
        OpEventCertificateElementGetByIndex_Ssa_TrustModelEcuCert_ext_pkiRole_006_CertificateElementGetByIndex_KeyMCertificateE_d3f88221: start-on-event=CertificateElementGetByIndex_Ssa_TrustModelEcuCert_ext_pkiRole_006, operation=KeyMCertificateElement_Ssa_TrustModelEcuCert_ext_pkiRole_006.CertificateElementGetByIndex
        OpEventCertElementGet_Ssa_TrustModelBackendCert_signatureAlgorithm_002_CertificateElementGet_KeyMCertificateElement_Ssa_3b98f3ab: start-on-event=CertElementGet_Ssa_TrustModelBackendCert_signatureAlgorithm_002, operation=KeyMCertificateElement_Ssa_TrustModelBackendCert_signatureAlgorithm_002.CertificateElementGet
        OpEventCertificateElementGetByIndex_Ssa_TrustModelEcuCert_ext_authKeyId_005_CertificateElementGetByIndex_KeyMCertificat_e650119b: start-on-event=CertificateElementGetByIndex_Ssa_TrustModelEcuCert_ext_authKeyId_005, operation=KeyMCertificateElement_Ssa_TrustModelEcuCert_ext_authKeyId_005.CertificateElementGetByIndex
        OpEventCertElementGet_Ssa_TrustModelRootCert_Version_CertificateElementGet_KeyMCertificateElement_Ssa_TrustModelRootCert_Version: start-on-event=CertElementGet_Ssa_TrustModelRootCert_Version, operation=KeyMCertificateElement_Ssa_TrustModelRootCert_Version.CertificateElementGet
        OpEventCertElementGet_Ssa_TrustModelRootCert_ext_basicConstraints_CertificateElementGet_KeyMCertificateElement_Ssa_Trus_6cbfb979: start-on-event=CertElementGet_Ssa_TrustModelRootCert_ext_basicConstraints, operation=KeyMCertificateElement_Ssa_TrustModelRootCert_ext_basicConstraints.CertificateElementGet
        OpEventCertElementGet_Ssa_TrustModelEcuCert_ext_specialEcu_005_CertificateElementGet_KeyMCertificateElement_Ssa_TrustMo_e95b22d8: start-on-event=CertElementGet_Ssa_TrustModelEcuCert_ext_specialEcu_005, operation=KeyMCertificateElement_Ssa_TrustModelEcuCert_ext_specialEcu_005.CertificateElementGet
        OpEventCertElementGet_Ssa_TrustModelIntermediateCert_ext_authKeyId_003_CertificateElementGet_KeyMCertificateElement_Ssa_75ac5376: start-on-event=CertElementGet_Ssa_TrustModelIntermediateCert_ext_authKeyId_003, operation=KeyMCertificateElement_Ssa_TrustModelIntermediateCert_ext_authKeyId_003.CertificateElementGet
        OpEventCertificateElementGetByIndex_Ssa_TrustModelEcuCsr_validityNotBefore_008_CertificateElementGetByIndex_KeyMCertifi_2d9fa804: start-on-event=CertificateElementGetByIndex_Ssa_TrustModelEcuCsr_validityNotBefore_008, operation=KeyMCertificateElement_Ssa_TrustModelEcuCsr_validityNotBefore_008.CertificateElementGetByIndex
        OpEventCertificateElementGetByIndex_Ssa_TrustModelEcuCsr_signatureAlgorithm_008_CertificateElementGetByIndex_KeyMCertif_6a9a73b1: start-on-event=CertificateElementGetByIndex_Ssa_TrustModelEcuCsr_signatureAlgorithm_008, operation=KeyMCertificateElement_Ssa_TrustModelEcuCsr_signatureAlgorithm_008.CertificateElementGetByIndex
        OpEventCertElementGet_Ssa_TrustModelIntermediatePeerCert_signatureAlgorithm_007_CertificateElementGet_KeyMCertificateEl_178c3cec: start-on-event=CertElementGet_Ssa_TrustModelIntermediatePeerCert_signatureAlgorithm_007, operation=KeyMCertificateElement_Ssa_TrustModelIntermediatePeerCert_signatureAlgorithm_007.CertificateElementGet
        OpEventCertElementGet_Ssa_TrustModelEcuPeerCert_Issuer_006_CertificateElementGet_KeyMCertificateElement_Ssa_TrustModelE_f85ceb1c: start-on-event=CertElementGet_Ssa_TrustModelEcuPeerCert_Issuer_006, operation=KeyMCertificateElement_Ssa_TrustModelEcuPeerCert_Issuer_006.CertificateElementGet
        OpEventCertificateElementGetByIndex_Ssa_TrustModelEcuPeerCert_Issuer_006_CertificateElementGetByIndex_KeyMCertificateEl_ce31a8ca: start-on-event=CertificateElementGetByIndex_Ssa_TrustModelEcuPeerCert_Issuer_006, operation=KeyMCertificateElement_Ssa_TrustModelEcuPeerCert_Issuer_006.CertificateElementGetByIndex
        OpEventCertElementGet_Ssa_TrustModelBackendPeerCert_ext_authKeyId_004_CertificateElementGet_KeyMCertificateElement_Ssa_016b2886: start-on-event=CertElementGet_Ssa_TrustModelBackendPeerCert_ext_authKeyId_004, operation=KeyMCertificateElement_Ssa_TrustModelBackendPeerCert_ext_authKeyId_004.CertificateElementGet
        OpEventCertElementGet_Ssa_TrustModelBackendCert_SubjectPublicKeyInfoKey_002_CertificateElementGet_KeyMCertificateElemen_5a951884: start-on-event=CertElementGet_Ssa_TrustModelBackendCert_SubjectPublicKeyInfoKey_002, operation=KeyMCertificateElement_Ssa_TrustModelBackendCert_SubjectPublicKeyInfoKey_002.CertificateElementGet
        OpEventCertElementGet_Ssa_TrustModelBackendCert_validityNotBefore_002_CertificateElementGet_KeyMCertificateElement_Ssa_76cf2b23: start-on-event=CertElementGet_Ssa_TrustModelBackendCert_validityNotBefore_002, operation=KeyMCertificateElement_Ssa_TrustModelBackendCert_validityNotBefore_002.CertificateElementGet
        OpEventCertificateElementGetByIndex_Ssa_TrustModelBackendPeerCert_SubjectPublicKeyInfoKey_004_CertificateElementGetByIn_6e7232c1: start-on-event=CertificateElementGetByIndex_Ssa_TrustModelBackendPeerCert_SubjectPublicKeyInfoKey_004, operation=KeyMCertificateElement_Ssa_TrustModelBackendPeerCert_SubjectPublicKeyInfoKey_004.CertificateElementGetByIndex
        OpEventCertElementGet_Ssa_TrustModelEcuCsr_SubjectPublicKeyInfoAlgo_008_CertificateElementGet_KeyMCertificateElement_Ss_34c1160c: start-on-event=CertElementGet_Ssa_TrustModelEcuCsr_SubjectPublicKeyInfoAlgo_008, operation=KeyMCertificateElement_Ssa_TrustModelEcuCsr_SubjectPublicKeyInfoAlgo_008.CertificateElementGet
        OpEventCertificateElementGetByIndex_Ssa_TrustModelIntermediateCert_ext_pkiRole_003_CertificateElementGetByIndex_KeyMCer_6b48178c: start-on-event=CertificateElementGetByIndex_Ssa_TrustModelIntermediateCert_ext_pkiRole_003, operation=KeyMCertificateElement_Ssa_TrustModelIntermediateCert_ext_pkiRole_003.CertificateElementGetByIndex
        OpEventCertElementGet_Ssa_TrustModelIntermediatePeerCert_Issuer_007_CertificateElementGet_KeyMCertificateElement_Ssa_Tr_5792cc6d: start-on-event=CertElementGet_Ssa_TrustModelIntermediatePeerCert_Issuer_007, operation=KeyMCertificateElement_Ssa_TrustModelIntermediatePeerCert_Issuer_007.CertificateElementGet
        OpEventCertElementGet_Ssa_TrustModelIntermediatePeerCert_ext_keyUsage_007_CertificateElementGet_KeyMCertificateElement_312ee28f: start-on-event=CertElementGet_Ssa_TrustModelIntermediatePeerCert_ext_keyUsage_007, operation=KeyMCertificateElement_Ssa_TrustModelIntermediatePeerCert_ext_keyUsage_007.CertificateElementGet
        OpEventCertificateElementGetByIndex_Ssa_TrustModelEcuCsr_ext_authKeyId_008_CertificateElementGetByIndex_KeyMCertificate_4ae22462: start-on-event=CertificateElementGetByIndex_Ssa_TrustModelEcuCsr_ext_authKeyId_008, operation=KeyMCertificateElement_Ssa_TrustModelEcuCsr_ext_authKeyId_008.CertificateElementGetByIndex
        OpEventCertificateElementGetByIndex_Ssa_TrustModelBackendCert_signatureAlgorithm_002_CertificateElementGetByIndex_KeyMC_2d2abe5e: start-on-event=CertificateElementGetByIndex_Ssa_TrustModelBackendCert_signatureAlgorithm_002, operation=KeyMCertificateElement_Ssa_TrustModelBackendCert_signatureAlgorithm_002.CertificateElementGetByIndex
        OpEventCertificateElementGetByIndex_Ssa_TrustModelEcuCsr_SigAlgoId_008_CertificateElementGetByIndex_KeyMCertificateElem_b6ab6a93: start-on-event=CertificateElementGetByIndex_Ssa_TrustModelEcuCsr_SigAlgoId_008, operation=KeyMCertificateElement_Ssa_TrustModelEcuCsr_SigAlgoId_008.CertificateElementGetByIndex
        OpEventCertificateElementGetByIndex_Ssa_TrustModelEcuCsr_validityNotAfter_008_CertificateElementGetByIndex_KeyMCertific_92b1cac9: start-on-event=CertificateElementGetByIndex_Ssa_TrustModelEcuCsr_validityNotAfter_008, operation=KeyMCertificateElement_Ssa_TrustModelEcuCsr_validityNotAfter_008.CertificateElementGetByIndex
        OpEventCertificateElementGetByIndex_Ssa_TrustModelIntermediateCert_Version_003_CertificateElementGetByIndex_KeyMCertifi_c77694bf: start-on-event=CertificateElementGetByIndex_Ssa_TrustModelIntermediateCert_Version_003, operation=KeyMCertificateElement_Ssa_TrustModelIntermediateCert_Version_003.CertificateElementGetByIndex
        OpEventCertElementGet_Ssa_TrustModelBackendCert_ext_keyUsage_002_CertificateElementGet_KeyMCertificateElement_Ssa_Trust_aec761cf: start-on-event=CertElementGet_Ssa_TrustModelBackendCert_ext_keyUsage_002, operation=KeyMCertificateElement_Ssa_TrustModelBackendCert_ext_keyUsage_002.CertificateElementGet
        OpEventCertificateElementGetByIndex_Ssa_TrustModelBackendPeerCert_validityNotAfter_004_CertificateElementGetByIndex_Key_1af1177b: start-on-event=CertificateElementGetByIndex_Ssa_TrustModelBackendPeerCert_validityNotAfter_004, operation=KeyMCertificateElement_Ssa_TrustModelBackendPeerCert_validityNotAfter_004.CertificateElementGetByIndex
        OpEventCertElementGet_Ssa_TrustModelBackendPeerCert_Issuer_004_CertificateElementGet_KeyMCertificateElement_Ssa_TrustMo_bef88922: start-on-event=CertElementGet_Ssa_TrustModelBackendPeerCert_Issuer_004, operation=KeyMCertificateElement_Ssa_TrustModelBackendPeerCert_Issuer_004.CertificateElementGet
        OpEventCertificateElementGetByIndex_Ssa_TrustModelRootCert_SubjectPublicKeyInfoAlgo_CertificateElementGetByIndex_KeyMCe_2de55623: start-on-event=CertificateElementGetByIndex_Ssa_TrustModelRootCert_SubjectPublicKeyInfoAlgo, operation=KeyMCertificateElement_Ssa_TrustModelRootCert_SubjectPublicKeyInfoAlgo.CertificateElementGetByIndex
        OpEventCertificateElementGetByIndex_Ssa_TrustModelEcuPeerCert_validityNotAfter_006_CertificateElementGetByIndex_KeyMCer_3d437c9c: start-on-event=CertificateElementGetByIndex_Ssa_TrustModelEcuPeerCert_validityNotAfter_006, operation=KeyMCertificateElement_Ssa_TrustModelEcuPeerCert_validityNotAfter_006.CertificateElementGetByIndex
        OpEventCertElementGet_Ssa_TrustModelEcuCert_validityNotBefore_005_CertificateElementGet_KeyMCertificateElement_Ssa_Trus_de3800a1: start-on-event=CertElementGet_Ssa_TrustModelEcuCert_validityNotBefore_005, operation=KeyMCertificateElement_Ssa_TrustModelEcuCert_validityNotBefore_005.CertificateElementGet
        OpEventCertificateElementGetByIndex_Ssa_TrustModelIntermediatePeerCert_SerialNo_007_CertificateElementGetByIndex_KeyMCe_fb17e618: start-on-event=CertificateElementGetByIndex_Ssa_TrustModelIntermediatePeerCert_SerialNo_007, operation=KeyMCertificateElement_Ssa_TrustModelIntermediatePeerCert_SerialNo_007.CertificateElementGetByIndex
        OpEventCertificateElementGetByIndex_Ssa_TrustModelIntermediatePeerCert_ext_basicConstraints_005_CertificateElementGetBy_ba07014c: start-on-event=CertificateElementGetByIndex_Ssa_TrustModelIntermediatePeerCert_ext_basicConstraints_005, operation=KeyMCertificateElement_Ssa_TrustModelIntermediatePeerCert_ext_basicConstraints_005.CertificateElementGetByIndex
        OpEventCertificateElementGetByIndex_Ssa_TrustModelEcuPeerCert_subject_006_CertificateElementGetByIndex_KeyMCertificateE_13dbcb43: start-on-event=CertificateElementGetByIndex_Ssa_TrustModelEcuPeerCert_subject_006, operation=KeyMCertificateElement_Ssa_TrustModelEcuPeerCert_subject_006.CertificateElementGetByIndex
        OpEventCertificateElementGetByIndex_Ssa_TrustModelRootCert_SigAlgoId_CertificateElementGetByIndex_KeyMCertificateElemen_86f83cc9: start-on-event=CertificateElementGetByIndex_Ssa_TrustModelRootCert_SigAlgoId, operation=KeyMCertificateElement_Ssa_TrustModelRootCert_SigAlgoId.CertificateElementGetByIndex
        OpEventCertificateElementGetByIndex_Ssa_TrustModelEcuCert_ext_uniqueECUID_005_CertificateElementGetByIndex_KeyMCertific_769ae881: start-on-event=CertificateElementGetByIndex_Ssa_TrustModelEcuCert_ext_uniqueECUID_005, operation=KeyMCertificateElement_Ssa_TrustModelEcuCert_ext_uniqueECUID_005.CertificateElementGetByIndex
        OpEventCertificateElementGetByIndex_Ssa_TrustModelIntermediatePeerCert_ext_pkiRole_005_CertificateElementGetByIndex_Key_7b54d4cb: start-on-event=CertificateElementGetByIndex_Ssa_TrustModelIntermediatePeerCert_ext_pkiRole_005, operation=KeyMCertificateElement_Ssa_TrustModelIntermediatePeerCert_ext_pkiRole_005.CertificateElementGetByIndex
        OpEventCertElementGet_Ssa_TrustModelEcuPeerCert_validityNotAfter_006_CertificateElementGet_KeyMCertificateElement_Ssa_T_1679dc66: start-on-event=CertElementGet_Ssa_TrustModelEcuPeerCert_validityNotAfter_006, operation=KeyMCertificateElement_Ssa_TrustModelEcuPeerCert_validityNotAfter_006.CertificateElementGet
        OpEventCertElementGet_Ssa_TrustModelRootCert_ext_keyUsage_CertificateElementGet_KeyMCertificateElement_Ssa_TrustModelRo_7c954924: start-on-event=CertElementGet_Ssa_TrustModelRootCert_ext_keyUsage, operation=KeyMCertificateElement_Ssa_TrustModelRootCert_ext_keyUsage.CertificateElementGet
        OpEventCertificateElementGetByIndex_Ssa_TrustModelIntermediatePeerCert_Issuer_007_CertificateElementGetByIndex_KeyMCert_b849be81: start-on-event=CertificateElementGetByIndex_Ssa_TrustModelIntermediatePeerCert_Issuer_007, operation=KeyMCertificateElement_Ssa_TrustModelIntermediatePeerCert_Issuer_007.CertificateElementGetByIndex
        OpEventCertElementGet_Ssa_TrustModelEcuCsr_ext_extKeyUsage_oid2_007_CertificateElementGet_KeyMCertificateElement_Ssa_Tr_7dc24666: start-on-event=CertElementGet_Ssa_TrustModelEcuCsr_ext_extKeyUsage_oid2_007, operation=KeyMCertificateElement_Ssa_TrustModelEcuCsr_ext_extKeyUsage_oid2_007.CertificateElementGet
        OpEventCertElementGet_Ssa_TrustModelEcuCert_ext_subKeyId_005_CertificateElementGet_KeyMCertificateElement_Ssa_TrustMode_e88ee1d1: start-on-event=CertElementGet_Ssa_TrustModelEcuCert_ext_subKeyId_005, operation=KeyMCertificateElement_Ssa_TrustModelEcuCert_ext_subKeyId_005.CertificateElementGet
        OpEventCertElementGet_Ssa_TrustModelIntermediateCert_validityNotBefore_003_CertificateElementGet_KeyMCertificateElement_4bd4822d: start-on-event=CertElementGet_Ssa_TrustModelIntermediateCert_validityNotBefore_003, operation=KeyMCertificateElement_Ssa_TrustModelIntermediateCert_validityNotBefore_003.CertificateElementGet
        OpEventCertElementGet_Ssa_TrustModelIntermediatePeerCert_ext_authKeyId_007_CertificateElementGet_KeyMCertificateElement_f17083f6: start-on-event=CertElementGet_Ssa_TrustModelIntermediatePeerCert_ext_authKeyId_007, operation=KeyMCertificateElement_Ssa_TrustModelIntermediatePeerCert_ext_authKeyId_007.CertificateElementGet
        OpEventCertificateElementGetByIndex_Ssa_TrustModelIntermediatePeerCert_validityNotAfter_007_CertificateElementGetByInde_a06fe10a: start-on-event=CertificateElementGetByIndex_Ssa_TrustModelIntermediatePeerCert_validityNotAfter_007, operation=KeyMCertificateElement_Ssa_TrustModelIntermediatePeerCert_validityNotAfter_007.CertificateElementGetByIndex
        OpEventCertElementGet_Ssa_TrustModelEcuCsr_ext_keyUsage_008_CertificateElementGet_KeyMCertificateElement_Ssa_TrustModel_6f51a83a: start-on-event=CertElementGet_Ssa_TrustModelEcuCsr_ext_keyUsage_008, operation=KeyMCertificateElement_Ssa_TrustModelEcuCsr_ext_keyUsage_008.CertificateElementGet
        OpEventCertificateElementGetByIndex_Ssa_TrustModelEcuCsr_subject_008_CertificateElementGetByIndex_KeyMCertificateElemen_7be51889: start-on-event=CertificateElementGetByIndex_Ssa_TrustModelEcuCsr_subject_008, operation=KeyMCertificateElement_Ssa_TrustModelEcuCsr_subject_008.CertificateElementGetByIndex
        OpEventCertElementGet_Ssa_TrustModelRootCert_Issuer_CertificateElementGet_KeyMCertificateElement_Ssa_TrustModelRootCert_Issuer: start-on-event=CertElementGet_Ssa_TrustModelRootCert_Issuer, operation=KeyMCertificateElement_Ssa_TrustModelRootCert_Issuer.CertificateElementGet
        OpEventCertElementGet_Ssa_TrustModelEcuPeerCert_SubjectPublicKeyInfoAlgo_006_CertificateElementGet_KeyMCertificateEleme_1be761c2: start-on-event=CertElementGet_Ssa_TrustModelEcuPeerCert_SubjectPublicKeyInfoAlgo_006, operation=KeyMCertificateElement_Ssa_TrustModelEcuPeerCert_SubjectPublicKeyInfoAlgo_006.CertificateElementGet
        OpEventCertElementGet_Ssa_TrustModelIntermediatePeerCert_validityNotAfter_007_CertificateElementGet_KeyMCertificateElem_392bbe5b: start-on-event=CertElementGet_Ssa_TrustModelIntermediatePeerCert_validityNotAfter_007, operation=KeyMCertificateElement_Ssa_TrustModelIntermediatePeerCert_validityNotAfter_007.CertificateElementGet
        OpEventCertificateElementGetByIndex_Ssa_TrustModelEcuCsr_ext_keyUsage_008_CertificateElementGetByIndex_KeyMCertificateE_e65962ee: start-on-event=CertificateElementGetByIndex_Ssa_TrustModelEcuCsr_ext_keyUsage_008, operation=KeyMCertificateElement_Ssa_TrustModelEcuCsr_ext_keyUsage_008.CertificateElementGetByIndex
        OpEventCertElementGet_Ssa_TrustModelIntermediateCert_SubjectPublicKeyInfoAlgo_003_CertificateElementGet_KeyMCertificate_93113cb9: start-on-event=CertElementGet_Ssa_TrustModelIntermediateCert_SubjectPublicKeyInfoAlgo_003, operation=KeyMCertificateElement_Ssa_TrustModelIntermediateCert_SubjectPublicKeyInfoAlgo_003.CertificateElementGet
        OpEventCertificateElementGetByIndex_Ssa_TrustModelRootCert_ext_subKeyId_CertificateElementGetByIndex_KeyMCertificateEle_efaad842: start-on-event=CertificateElementGetByIndex_Ssa_TrustModelRootCert_ext_subKeyId, operation=KeyMCertificateElement_Ssa_TrustModelRootCert_ext_subKeyId.CertificateElementGetByIndex
        OpEventCertificateElementGetByIndex_Ssa_TrustModelEcuCsr_ext_pkiRole_008_CertificateElementGetByIndex_KeyMCertificateEl_7d6b1687: start-on-event=CertificateElementGetByIndex_Ssa_TrustModelEcuCsr_ext_pkiRole_008, operation=KeyMCertificateElement_Ssa_TrustModelEcuCsr_ext_pkiRole_008.CertificateElementGetByIndex
        OpEventCertElementGet_Ssa_TrustModelEcuPeerCert_Version_006_CertificateElementGet_KeyMCertificateElement_Ssa_TrustModel_e9136fee: start-on-event=CertElementGet_Ssa_TrustModelEcuPeerCert_Version_006, operation=KeyMCertificateElement_Ssa_TrustModelEcuPeerCert_Version_006.CertificateElementGet
        OpEventCertificateElementGetByIndex_Ssa_TrustModelBackendPeerCert_signatureAlgorithm_004_CertificateElementGetByIndex_K_e8959801: start-on-event=CertificateElementGetByIndex_Ssa_TrustModelBackendPeerCert_signatureAlgorithm_004, operation=KeyMCertificateElement_Ssa_TrustModelBackendPeerCert_signatureAlgorithm_004.CertificateElementGetByIndex
        OpEventCertElementGet_Ssa_TrustModelBackendPeerCert_Version_004_CertificateElementGet_KeyMCertificateElement_Ssa_TrustM_f31c9bdf: start-on-event=CertElementGet_Ssa_TrustModelBackendPeerCert_Version_004, operation=KeyMCertificateElement_Ssa_TrustModelBackendPeerCert_Version_004.CertificateElementGet
        OpEventCertificateElementGetByIndex_Ssa_TrustModelIntermediateCert_SerialNo_003_CertificateElementGetByIndex_KeyMCertif_59eed541: start-on-event=CertificateElementGetByIndex_Ssa_TrustModelIntermediateCert_SerialNo_003, operation=KeyMCertificateElement_Ssa_TrustModelIntermediateCert_SerialNo_003.CertificateElementGetByIndex
        OpEventCertElementGet_Ssa_TrustModelIntermediateCert_SubjectPublicKeyInfoKey_003_CertificateElementGet_KeyMCertificateE_fd11b10c: start-on-event=CertElementGet_Ssa_TrustModelIntermediateCert_SubjectPublicKeyInfoKey_003, operation=KeyMCertificateElement_Ssa_TrustModelIntermediateCert_SubjectPublicKeyInfoKey_003.CertificateElementGet
        OpEventCertElementGet_Ssa_TrustModelRootCert_signatureAlgorithm_CertificateElementGet_KeyMCertificateElement_Ssa_TrustM_0e61c721: start-on-event=CertElementGet_Ssa_TrustModelRootCert_signatureAlgorithm, operation=KeyMCertificateElement_Ssa_TrustModelRootCert_signatureAlgorithm.CertificateElementGet
        OpEventCertElementGet_Ssa_TrustModelEcuCert_ext_pkiRole_006_CertificateElementGet_KeyMCertificateElement_Ssa_TrustModel_9284f135: start-on-event=CertElementGet_Ssa_TrustModelEcuCert_ext_pkiRole_006, operation=KeyMCertificateElement_Ssa_TrustModelEcuCert_ext_pkiRole_006.CertificateElementGet
        OpEventCertElementGet_Ssa_TrustModelEcuPeerCert_signatureAlgorithm_006_CertificateElementGet_KeyMCertificateElement_Ssa_150ef24f: start-on-event=CertElementGet_Ssa_TrustModelEcuPeerCert_signatureAlgorithm_006, operation=KeyMCertificateElement_Ssa_TrustModelEcuPeerCert_signatureAlgorithm_006.CertificateElementGet
        OpEventCertificateElementGetByIndex_Ssa_TrustModelRootCert_signatureValue_CertificateElementGetByIndex_KeyMCertificateE_4022ac98: start-on-event=CertificateElementGetByIndex_Ssa_TrustModelRootCert_signatureValue, operation=KeyMCertificateElement_Ssa_TrustModelRootCert_signatureValue.CertificateElementGetByIndex
        OpEventCertificateElementGetByIndex_Ssa_TrustModelEcuPeerCert_ext_uniqueECUID_006_CertificateElementGetByIndex_KeyMCert_8887d394: start-on-event=CertificateElementGetByIndex_Ssa_TrustModelEcuPeerCert_ext_uniqueECUID_006, operation=KeyMCertificateElement_Ssa_TrustModelEcuPeerCert_ext_uniqueECUID_006.CertificateElementGetByIndex
        OpEventCertificateElementGetByIndex_Ssa_TrustModelBackendPeerCert_validityNotBefore_004_CertificateElementGetByIndex_Ke_ec5db6ae: start-on-event=CertificateElementGetByIndex_Ssa_TrustModelBackendPeerCert_validityNotBefore_004, operation=KeyMCertificateElement_Ssa_TrustModelBackendPeerCert_validityNotBefore_004.CertificateElementGetByIndex
        OpEventCertElementGet_Ssa_TrustModelBackendCert_SubjectPublicKeyInfoAlgo_002_CertificateElementGet_KeyMCertificateEleme_4e9d85e4: start-on-event=CertElementGet_Ssa_TrustModelBackendCert_SubjectPublicKeyInfoAlgo_002, operation=KeyMCertificateElement_Ssa_TrustModelBackendCert_SubjectPublicKeyInfoAlgo_002.CertificateElementGet
        OpEventCertElementGet_Ssa_TrustModelEcuCsr_SubjectPublicKeyInfoKey_008_CertificateElementGet_KeyMCertificateElement_Ssa_08de19a0: start-on-event=CertElementGet_Ssa_TrustModelEcuCsr_SubjectPublicKeyInfoKey_008, operation=KeyMCertificateElement_Ssa_TrustModelEcuCsr_SubjectPublicKeyInfoKey_008.CertificateElementGet
        OpEventCertificateElementGetByIndex_Ssa_TrustModelBackendPeerCert_Version_004_CertificateElementGetByIndex_KeyMCertific_6dabad67: start-on-event=CertificateElementGetByIndex_Ssa_TrustModelBackendPeerCert_Version_004, operation=KeyMCertificateElement_Ssa_TrustModelBackendPeerCert_Version_004.CertificateElementGetByIndex
        OpEventCertificateElementGetByIndex_Ssa_TrustModelBackendCert_validityNotAfter_002_CertificateElementGetByIndex_KeyMCer_ddbe8542: start-on-event=CertificateElementGetByIndex_Ssa_TrustModelBackendCert_validityNotAfter_002, operation=KeyMCertificateElement_Ssa_TrustModelBackendCert_validityNotAfter_002.CertificateElementGetByIndex
        OpEventCertElementGet_Ssa_TrustModelBackendPeerCert_validityNotBefore_004_CertificateElementGet_KeyMCertificateElement_15b53a07: start-on-event=CertElementGet_Ssa_TrustModelBackendPeerCert_validityNotBefore_004, operation=KeyMCertificateElement_Ssa_TrustModelBackendPeerCert_validityNotBefore_004.CertificateElementGet
        OpEventCertElementGet_Ssa_TrustModelIntermediateCert_subject_003_CertificateElementGet_KeyMCertificateElement_Ssa_Trust_ce922e62: start-on-event=CertElementGet_Ssa_TrustModelIntermediateCert_subject_003, operation=KeyMCertificateElement_Ssa_TrustModelIntermediateCert_subject_003.CertificateElementGet
        OpEventCertElementGet_Ssa_TrustModelRootCert_ext_subKeyId_CertificateElementGet_KeyMCertificateElement_Ssa_TrustModelRo_dc1a99b5: start-on-event=CertElementGet_Ssa_TrustModelRootCert_ext_subKeyId, operation=KeyMCertificateElement_Ssa_TrustModelRootCert_ext_subKeyId.CertificateElementGet
        OpEventCertificateElementGetByIndex_Ssa_TrustModelBackendPeerCert_ext_keyUsage_004_CertificateElementGetByIndex_KeyMCer_4f2ef5d0: start-on-event=CertificateElementGetByIndex_Ssa_TrustModelBackendPeerCert_ext_keyUsage_004, operation=KeyMCertificateElement_Ssa_TrustModelBackendPeerCert_ext_keyUsage_004.CertificateElementGetByIndex
        OpEventCertificateElementGetByIndex_Ssa_TrustModelIntermediatePeerCert_signatureAlgorithm_007_CertificateElementGetByIn_07fe8e38: start-on-event=CertificateElementGetByIndex_Ssa_TrustModelIntermediatePeerCert_signatureAlgorithm_007, operation=KeyMCertificateElement_Ssa_TrustModelIntermediatePeerCert_signatureAlgorithm_007.CertificateElementGetByIndex
        OpEventCertElementGet_Ssa_TrustModelEcuCsr_ext_pkiRole_008_CertificateElementGet_KeyMCertificateElement_Ssa_TrustModelE_f5970be6: start-on-event=CertElementGet_Ssa_TrustModelEcuCsr_ext_pkiRole_008, operation=KeyMCertificateElement_Ssa_TrustModelEcuCsr_ext_pkiRole_008.CertificateElementGet
        OpEventCertElementGet_Ssa_TrustModelBackendCert_ext_basicConstraints_002_CertificateElementGet_KeyMCertificateElement_S_c3e18a20: start-on-event=CertElementGet_Ssa_TrustModelBackendCert_ext_basicConstraints_002, operation=KeyMCertificateElement_Ssa_TrustModelBackendCert_ext_basicConstraints_002.CertificateElementGet
        OpEventCertificateElementGetByIndex_Ssa_TrustModelIntermediateCert_validityNotAfter_003_CertificateElementGetByIndex_Ke_900f6512: start-on-event=CertificateElementGetByIndex_Ssa_TrustModelIntermediateCert_validityNotAfter_003, operation=KeyMCertificateElement_Ssa_TrustModelIntermediateCert_validityNotAfter_003.CertificateElementGetByIndex
        OpEventCertificateElementGetByIndex_Ssa_TrustModelEcuCsr_signatureValue_008_CertificateElementGetByIndex_KeyMCertificat_8a0cdb72: start-on-event=CertificateElementGetByIndex_Ssa_TrustModelEcuCsr_signatureValue_008, operation=KeyMCertificateElement_Ssa_TrustModelEcuCsr_signatureValue_008.CertificateElementGetByIndex
        OpEventCertificateElementGetByIndex_Ssa_TrustModelEcuPeerCert_validityNotBefore_006_CertificateElementGetByIndex_KeyMCe_356681c8: start-on-event=CertificateElementGetByIndex_Ssa_TrustModelEcuPeerCert_validityNotBefore_006, operation=KeyMCertificateElement_Ssa_TrustModelEcuPeerCert_validityNotBefore_006.CertificateElementGetByIndex
        OpEventCertElementGet_Ssa_TrustModelIntermediateCert_ext_pkiRole_003_CertificateElementGet_KeyMCertificateElement_Ssa_T_38b9a81c: start-on-event=CertElementGet_Ssa_TrustModelIntermediateCert_ext_pkiRole_003, operation=KeyMCertificateElement_Ssa_TrustModelIntermediateCert_ext_pkiRole_003.CertificateElementGet
        OpEventCertElementGet_Ssa_TrustModelEcuCsr_subject_008_CertificateElementGet_KeyMCertificateElement_Ssa_TrustModelEcuCs_d4018bd4: start-on-event=CertElementGet_Ssa_TrustModelEcuCsr_subject_008, operation=KeyMCertificateElement_Ssa_TrustModelEcuCsr_subject_008.CertificateElementGet
        OpEventCertificateElementGetByIndex_Ssa_TrustModelBackendCert_SubjectPublicKeyInfoKey_002_CertificateElementGetByIndex_ed929204: start-on-event=CertificateElementGetByIndex_Ssa_TrustModelBackendCert_SubjectPublicKeyInfoKey_002, operation=KeyMCertificateElement_Ssa_TrustModelBackendCert_SubjectPublicKeyInfoKey_002.CertificateElementGetByIndex
        OpEventCertElementGet_Ssa_TrustModelBackendPeerCert_ext_subKeyId_004_CertificateElementGet_KeyMCertificateElement_Ssa_T_29388ff3: start-on-event=CertElementGet_Ssa_TrustModelBackendPeerCert_ext_subKeyId_004, operation=KeyMCertificateElement_Ssa_TrustModelBackendPeerCert_ext_subKeyId_004.CertificateElementGet
        OpEventCertificateElementGetByIndex_Ssa_TrustModelIntermediateCert_validityNotBefore_003_CertificateElementGetByIndex_K_11d9f1f0: start-on-event=CertificateElementGetByIndex_Ssa_TrustModelIntermediateCert_validityNotBefore_003, operation=KeyMCertificateElement_Ssa_TrustModelIntermediateCert_validityNotBefore_003.CertificateElementGetByIndex
        OpEventCertElementGet_Ssa_TrustModelEcuPeerCert_ext_specialEcu_006_CertificateElementGet_KeyMCertificateElement_Ssa_Tru_4eaa2647: start-on-event=CertElementGet_Ssa_TrustModelEcuPeerCert_ext_specialEcu_006, operation=KeyMCertificateElement_Ssa_TrustModelEcuPeerCert_ext_specialEcu_006.CertificateElementGet
        OpEventCertificateElementGetByIndex_Ssa_TrustModelBackendCert_SubjectPublicKeyInfoAlgo_002_CertificateElementGetByIndex_ac824834: start-on-event=CertificateElementGetByIndex_Ssa_TrustModelBackendCert_SubjectPublicKeyInfoAlgo_002, operation=KeyMCertificateElement_Ssa_TrustModelBackendCert_SubjectPublicKeyInfoAlgo_002.CertificateElementGetByIndex
        OpEventCertificateElementGetByIndex_Ssa_TrustModelBackendPeerCert_SigAlgoId_004_CertificateElementGetByIndex_KeyMCertif_851ab300: start-on-event=CertificateElementGetByIndex_Ssa_TrustModelBackendPeerCert_SigAlgoId_004, operation=KeyMCertificateElement_Ssa_TrustModelBackendPeerCert_SigAlgoId_004.CertificateElementGetByIndex
        OpEventCertElementGet_Ssa_TrustModelBackendPeerCert_signatureAlgorithm_004_CertificateElementGet_KeyMCertificateElement_daad144d: start-on-event=CertElementGet_Ssa_TrustModelBackendPeerCert_signatureAlgorithm_004, operation=KeyMCertificateElement_Ssa_TrustModelBackendPeerCert_signatureAlgorithm_004.CertificateElementGet
        OpEventCertElementGet_Ssa_TrustModelBackendPeerCert_ext_keyUsage_004_CertificateElementGet_KeyMCertificateElement_Ssa_T_02b62f8c: start-on-event=CertElementGet_Ssa_TrustModelBackendPeerCert_ext_keyUsage_004, operation=KeyMCertificateElement_Ssa_TrustModelBackendPeerCert_ext_keyUsage_004.CertificateElementGet
        OpEventCertElementGet_Ssa_TrustModelBackendCert_signatureValue_002_CertificateElementGet_KeyMCertificateElement_Ssa_Tru_906ab4f7: start-on-event=CertElementGet_Ssa_TrustModelBackendCert_signatureValue_002, operation=KeyMCertificateElement_Ssa_TrustModelBackendCert_signatureValue_002.CertificateElementGet
        OpEventCertElementGet_Ssa_TrustModelEcuCert_ext_authKeyId_005_CertificateElementGet_KeyMCertificateElement_Ssa_TrustMod_63cc51a3: start-on-event=CertElementGet_Ssa_TrustModelEcuCert_ext_authKeyId_005, operation=KeyMCertificateElement_Ssa_TrustModelEcuCert_ext_authKeyId_005.CertificateElementGet
        OpEventCertElementGet_Ssa_TrustModelEcuCert_ext_uniqueECUID_005_CertificateElementGet_KeyMCertificateElement_Ssa_TrustM_a0ca3a3e: start-on-event=CertElementGet_Ssa_TrustModelEcuCert_ext_uniqueECUID_005, operation=KeyMCertificateElement_Ssa_TrustModelEcuCert_ext_uniqueECUID_005.CertificateElementGet
        OpEventCertificateElementGetByIndex_Ssa_TrustModelEcuCert_SubjectPublicKeyInfoKey_005_CertificateElementGetByIndex_KeyM_e7343485: start-on-event=CertificateElementGetByIndex_Ssa_TrustModelEcuCert_SubjectPublicKeyInfoKey_005, operation=KeyMCertificateElement_Ssa_TrustModelEcuCert_SubjectPublicKeyInfoKey_005.CertificateElementGetByIndex
        OpEventCertificateElementGetByIndex_Ssa_TrustModelEcuPeerCert_SerialNo_006_CertificateElementGetByIndex_KeyMCertificate_75d38d3c: start-on-event=CertificateElementGetByIndex_Ssa_TrustModelEcuPeerCert_SerialNo_006, operation=KeyMCertificateElement_Ssa_TrustModelEcuPeerCert_SerialNo_006.CertificateElementGetByIndex
        OpEventCertElementGet_Ssa_TrustModelIntermediatePeerCert_SigAlgoId_007_CertificateElementGet_KeyMCertificateElement_Ssa_22caa3f8: start-on-event=CertElementGet_Ssa_TrustModelIntermediatePeerCert_SigAlgoId_007, operation=KeyMCertificateElement_Ssa_TrustModelIntermediatePeerCert_SigAlgoId_007.CertificateElementGet
        OpEventCertElementGet_Ssa_TrustModelEcuCsr_validityNotAfter_008_CertificateElementGet_KeyMCertificateElement_Ssa_TrustM_2a02b530: start-on-event=CertElementGet_Ssa_TrustModelEcuCsr_validityNotAfter_008, operation=KeyMCertificateElement_Ssa_TrustModelEcuCsr_validityNotAfter_008.CertificateElementGet
        OpEventCertElementGet_Ssa_TrustModelEcuPeerCert_ext_uniqueECUID_006_CertificateElementGet_KeyMCertificateElement_Ssa_Tr_94bd825d: start-on-event=CertElementGet_Ssa_TrustModelEcuPeerCert_ext_uniqueECUID_006, operation=KeyMCertificateElement_Ssa_TrustModelEcuPeerCert_ext_uniqueECUID_006.CertificateElementGet
        OpEventCertificateElementGetByIndex_Ssa_TrustModelEcuPeerCert_Version_006_CertificateElementGetByIndex_KeyMCertificateE_6fec1f52: start-on-event=CertificateElementGetByIndex_Ssa_TrustModelEcuPeerCert_Version_006, operation=KeyMCertificateElement_Ssa_TrustModelEcuPeerCert_Version_006.CertificateElementGetByIndex
        OpEventCertElementGet_Ssa_TrustModelIntermediateCert_Issuer_003_CertificateElementGet_KeyMCertificateElement_Ssa_TrustM_475a0b9e: start-on-event=CertElementGet_Ssa_TrustModelIntermediateCert_Issuer_003, operation=KeyMCertificateElement_Ssa_TrustModelIntermediateCert_Issuer_003.CertificateElementGet
        OpEventCertElementGet_Ssa_TrustModelIntermediatePeerCert_Version_007_CertificateElementGet_KeyMCertificateElement_Ssa_T_86a0ce36: start-on-event=CertElementGet_Ssa_TrustModelIntermediatePeerCert_Version_007, operation=KeyMCertificateElement_Ssa_TrustModelIntermediatePeerCert_Version_007.CertificateElementGet
        OpEventCertificateElementGetByIndex_Ssa_TrustModelEcuPeerCert_signatureAlgorithm_006_CertificateElementGetByIndex_KeyMC_850509ec: start-on-event=CertificateElementGetByIndex_Ssa_TrustModelEcuPeerCert_signatureAlgorithm_006, operation=KeyMCertificateElement_Ssa_TrustModelEcuPeerCert_signatureAlgorithm_006.CertificateElementGetByIndex
        OpEventCertificateElementGetByIndex_Ssa_TrustModelIntermediatePeerCert_ext_authKeyId_007_CertificateElementGetByIndex_K_7c2c89bb: start-on-event=CertificateElementGetByIndex_Ssa_TrustModelIntermediatePeerCert_ext_authKeyId_007, operation=KeyMCertificateElement_Ssa_TrustModelIntermediatePeerCert_ext_authKeyId_007.CertificateElementGetByIndex
        OpEventCertificateElementGetByIndex_Ssa_TrustModelBackendPeerCert_subject_004_CertificateElementGetByIndex_KeyMCertific_92d7051a: start-on-event=CertificateElementGetByIndex_Ssa_TrustModelBackendPeerCert_subject_004, operation=KeyMCertificateElement_Ssa_TrustModelBackendPeerCert_subject_004.CertificateElementGetByIndex
        OpEventCertificateElementGetByIndex_Ssa_TrustModelEcuCert_ext_specialEcu_005_CertificateElementGetByIndex_KeyMCertifica_41b98435: start-on-event=CertificateElementGetByIndex_Ssa_TrustModelEcuCert_ext_specialEcu_005, operation=KeyMCertificateElement_Ssa_TrustModelEcuCert_ext_specialEcu_005.CertificateElementGetByIndex
        OpEventCertificateElementGetByIndex_Ssa_TrustModelBackendCert_ext_pkiRole_002_CertificateElementGetByIndex_KeyMCertific_2b2ea044: start-on-event=CertificateElementGetByIndex_Ssa_TrustModelBackendCert_ext_pkiRole_002, operation=KeyMCertificateElement_Ssa_TrustModelBackendCert_ext_pkiRole_002.CertificateElementGetByIndex
        OpEventCertElementGet_Ssa_TrustModelRootCert_validityNotBefore_CertificateElementGet_KeyMCertificateElement_Ssa_TrustMo_35dc792c: start-on-event=CertElementGet_Ssa_TrustModelRootCert_validityNotBefore, operation=KeyMCertificateElement_Ssa_TrustModelRootCert_validityNotBefore.CertificateElementGet
        OpEventCertificateElementGetByIndex_Ssa_TrustModelBackendPeerCert_ext_subKeyId_004_CertificateElementGetByIndex_KeyMCer_750a24fe: start-on-event=CertificateElementGetByIndex_Ssa_TrustModelBackendPeerCert_ext_subKeyId_004, operation=KeyMCertificateElement_Ssa_TrustModelBackendPeerCert_ext_subKeyId_004.CertificateElementGetByIndex
        OpEventCertElementGet_Ssa_TrustModelEcuCsr_signatureAlgorithm_008_CertificateElementGet_KeyMCertificateElement_Ssa_Trus_f49f0bc9: start-on-event=CertElementGet_Ssa_TrustModelEcuCsr_signatureAlgorithm_008, operation=KeyMCertificateElement_Ssa_TrustModelEcuCsr_signatureAlgorithm_008.CertificateElementGet
        OpEventCertificateElementGetByIndex_Ssa_TrustModelEcuCert_SerialNo_005_CertificateElementGetByIndex_KeyMCertificateElem_f7501e4f: start-on-event=CertificateElementGetByIndex_Ssa_TrustModelEcuCert_SerialNo_005, operation=KeyMCertificateElement_Ssa_TrustModelEcuCert_SerialNo_005.CertificateElementGetByIndex
        OpEventCertElementGet_Ssa_TrustModelIntermediatePeerCert_SubjectPublicKeyInfoKey_007_CertificateElementGet_KeyMCertific_01615c74: start-on-event=CertElementGet_Ssa_TrustModelIntermediatePeerCert_SubjectPublicKeyInfoKey_007, operation=KeyMCertificateElement_Ssa_TrustModelIntermediatePeerCert_SubjectPublicKeyInfoKey_007.CertificateElementGet
        OpEventCertificateElementGetByIndex_Ssa_TrustModelIntermediatePeerCert_signatureValue_007_CertificateElementGetByIndex_d023dbd3: start-on-event=CertificateElementGetByIndex_Ssa_TrustModelIntermediatePeerCert_signatureValue_007, operation=KeyMCertificateElement_Ssa_TrustModelIntermediatePeerCert_signatureValue_007.CertificateElementGetByIndex
        OpEventCertElementGet_Ssa_TrustModelIntermediatePeerCert_subject_007_CertificateElementGet_KeyMCertificateElement_Ssa_T_749536d4: start-on-event=CertElementGet_Ssa_TrustModelIntermediatePeerCert_subject_007, operation=KeyMCertificateElement_Ssa_TrustModelIntermediatePeerCert_subject_007.CertificateElementGet
        OpEventCertElementGet_Ssa_TrustModelEcuPeerCert_ext_keyUsage_006_CertificateElementGet_KeyMCertificateElement_Ssa_Trust_2e3b9601: start-on-event=CertElementGet_Ssa_TrustModelEcuPeerCert_ext_keyUsage_006, operation=KeyMCertificateElement_Ssa_TrustModelEcuPeerCert_ext_keyUsage_006.CertificateElementGet
        OpEventCertificateElementGetByIndex_Ssa_TrustModelIntermediateCert_ext_keyUsage_003_CertificateElementGetByIndex_KeyMCe_fa666b13: start-on-event=CertificateElementGetByIndex_Ssa_TrustModelIntermediateCert_ext_keyUsage_003, operation=KeyMCertificateElement_Ssa_TrustModelIntermediateCert_ext_keyUsage_003.CertificateElementGetByIndex
        OpEventCertificateElementGetByIndex_Ssa_TrustModelBackendCert_validityNotBefore_002_CertificateElementGetByIndex_KeyMCe_2071e001: start-on-event=CertificateElementGetByIndex_Ssa_TrustModelBackendCert_validityNotBefore_002, operation=KeyMCertificateElement_Ssa_TrustModelBackendCert_validityNotBefore_002.CertificateElementGetByIndex
        OpEventCertElementGet_Ssa_TrustModelEcuCert_SigAlgoId_005_CertificateElementGet_KeyMCertificateElement_Ssa_TrustModelEc_b49974bc: start-on-event=CertElementGet_Ssa_TrustModelEcuCert_SigAlgoId_005, operation=KeyMCertificateElement_Ssa_TrustModelEcuCert_SigAlgoId_005.CertificateElementGet
        OpEventCertElementGet_Ssa_TrustModelEcuCsr_SerialNo_008_CertificateElementGet_KeyMCertificateElement_Ssa_TrustModelEcuC_eb3a1d1e: start-on-event=CertElementGet_Ssa_TrustModelEcuCsr_SerialNo_008, operation=KeyMCertificateElement_Ssa_TrustModelEcuCsr_SerialNo_008.CertificateElementGet
        OpEventCertificateElementGetByIndex_Ssa_TrustModelRootCert_ext_basicConstraints_CertificateElementGetByIndex_KeyMCertif_80722712: start-on-event=CertificateElementGetByIndex_Ssa_TrustModelRootCert_ext_basicConstraints, operation=KeyMCertificateElement_Ssa_TrustModelRootCert_ext_basicConstraints.CertificateElementGetByIndex
        OpEventCertElementGet_Ssa_TrustModelIntermediateCert_Version_003_CertificateElementGet_KeyMCertificateElement_Ssa_Trust_172c7dc2: start-on-event=CertElementGet_Ssa_TrustModelIntermediateCert_Version_003, operation=KeyMCertificateElement_Ssa_TrustModelIntermediateCert_Version_003.CertificateElementGet
        OpEventCertElementGet_Ssa_TrustModelBackendCert_SerialNo_002_CertificateElementGet_KeyMCertificateElement_Ssa_TrustMode_624ca7fb: start-on-event=CertElementGet_Ssa_TrustModelBackendCert_SerialNo_002, operation=KeyMCertificateElement_Ssa_TrustModelBackendCert_SerialNo_002.CertificateElementGet
        OpEventCertElementGet_Ssa_TrustModelRootCert_SubjectPublicKeyInfoKey_CertificateElementGet_KeyMCertificateElement_Ssa_T_b2bead89: start-on-event=CertElementGet_Ssa_TrustModelRootCert_SubjectPublicKeyInfoKey, operation=KeyMCertificateElement_Ssa_TrustModelRootCert_SubjectPublicKeyInfoKey.CertificateElementGet
        OpEventCertificateElementGetByIndex_Ssa_TrustModelIntermediatePeerCert_ext_subKeyId_007_CertificateElementGetByIndex_Ke_bd85ddb8: start-on-event=CertificateElementGetByIndex_Ssa_TrustModelIntermediatePeerCert_ext_subKeyId_007, operation=KeyMCertificateElement_Ssa_TrustModelIntermediatePeerCert_ext_subKeyId_007.CertificateElementGetByIndex
        OpEventCertElementGet_Ssa_TrustModelEcuCsr_ext_subKeyId_008_CertificateElementGet_KeyMCertificateElement_Ssa_TrustModel_ba94bae7: start-on-event=CertElementGet_Ssa_TrustModelEcuCsr_ext_subKeyId_008, operation=KeyMCertificateElement_Ssa_TrustModelEcuCsr_ext_subKeyId_008.CertificateElementGet
        OpEventCertElementGet_Ssa_TrustModelRootCert_SerialNo_CertificateElementGet_KeyMCertificateElement_Ssa_TrustModelRootCe_59c5de77: start-on-event=CertElementGet_Ssa_TrustModelRootCert_SerialNo, operation=KeyMCertificateElement_Ssa_TrustModelRootCert_SerialNo.CertificateElementGet
        OpEventCertElementGet_Ssa_TrustModelIntermediatePeerCert_signatureValue_007_CertificateElementGet_KeyMCertificateElemen_4eeeb0c2: start-on-event=CertElementGet_Ssa_TrustModelIntermediatePeerCert_signatureValue_007, operation=KeyMCertificateElement_Ssa_TrustModelIntermediatePeerCert_signatureValue_007.CertificateElementGet
        OpEventCertElementGet_Ssa_TrustModelEcuCsr_ext_uniqueECUID_007_CertificateElementGet_KeyMCertificateElement_Ssa_TrustMo_dd284538: start-on-event=CertElementGet_Ssa_TrustModelEcuCsr_ext_uniqueECUID_007, operation=KeyMCertificateElement_Ssa_TrustModelEcuCsr_ext_uniqueECUID_007.CertificateElementGet
        OpEventCertElementGet_Ssa_TrustModelIntermediateCert_ext_keyUsage_003_CertificateElementGet_KeyMCertificateElement_Ssa_22cbf412: start-on-event=CertElementGet_Ssa_TrustModelIntermediateCert_ext_keyUsage_003, operation=KeyMCertificateElement_Ssa_TrustModelIntermediateCert_ext_keyUsage_003.CertificateElementGet
        OpEventCertElementGet_Ssa_TrustModelBackendPeerCert_SubjectPublicKeyInfoKey_004_CertificateElementGet_KeyMCertificateEl_cc5f5ed1: start-on-event=CertElementGet_Ssa_TrustModelBackendPeerCert_SubjectPublicKeyInfoKey_004, operation=KeyMCertificateElement_Ssa_TrustModelBackendPeerCert_SubjectPublicKeyInfoKey_004.CertificateElementGet
        OpEventCertElementGet_Ssa_TrustModelEcuCsr_ext_authKeyId_008_CertificateElementGet_KeyMCertificateElement_Ssa_TrustMode_b1b63efb: start-on-event=CertElementGet_Ssa_TrustModelEcuCsr_ext_authKeyId_008, operation=KeyMCertificateElement_Ssa_TrustModelEcuCsr_ext_authKeyId_008.CertificateElementGet
        OpEventCertElementGet_Ssa_TrustModelBackendPeerCert_signatureValue_004_CertificateElementGet_KeyMCertificateElement_Ssa_1e4acf62: start-on-event=CertElementGet_Ssa_TrustModelBackendPeerCert_signatureValue_004, operation=KeyMCertificateElement_Ssa_TrustModelBackendPeerCert_signatureValue_004.CertificateElementGet
        OpEventCertificateElementGetByIndex_Ssa_TrustModelIntermediateCert_signatureAlgorithm_003_CertificateElementGetByIndex_c9dc2c63: start-on-event=CertificateElementGetByIndex_Ssa_TrustModelIntermediateCert_signatureAlgorithm_003, operation=KeyMCertificateElement_Ssa_TrustModelIntermediateCert_signatureAlgorithm_003.CertificateElementGetByIndex
        OpEventCertElementGet_Ssa_TrustModelIntermediateCert_signatureValue_003_CertificateElementGet_KeyMCertificateElement_Ss_2cdaa6f9: start-on-event=CertElementGet_Ssa_TrustModelIntermediateCert_signatureValue_003, operation=KeyMCertificateElement_Ssa_TrustModelIntermediateCert_signatureValue_003.CertificateElementGet
        OpEventCertificateElementGetByIndex_Ssa_TrustModelIntermediateCert_SigAlgoId_003_CertificateElementGetByIndex_KeyMCerti_4b2e4673: start-on-event=CertificateElementGetByIndex_Ssa_TrustModelIntermediateCert_SigAlgoId_003, operation=KeyMCertificateElement_Ssa_TrustModelIntermediateCert_SigAlgoId_003.CertificateElementGetByIndex
        OpEventCertificateElementGetByIndex_Ssa_TrustModelRootCert_validityNotBefore_CertificateElementGetByIndex_KeyMCertifica_f7713935: start-on-event=CertificateElementGetByIndex_Ssa_TrustModelRootCert_validityNotBefore, operation=KeyMCertificateElement_Ssa_TrustModelRootCert_validityNotBefore.CertificateElementGetByIndex
        OpEventCertElementGet_Ssa_TrustModelIntermediatePeerCert_ext_pkiRole_005_CertificateElementGet_KeyMCertificateElement_S_9dff9249: start-on-event=CertElementGet_Ssa_TrustModelIntermediatePeerCert_ext_pkiRole_005, operation=KeyMCertificateElement_Ssa_TrustModelIntermediatePeerCert_ext_pkiRole_005.CertificateElementGet
        OpEventCertElementGet_Ssa_TrustModelEcuCert_Version_005_CertificateElementGet_KeyMCertificateElement_Ssa_TrustModelEcuC_27d32666: start-on-event=CertElementGet_Ssa_TrustModelEcuCert_Version_005, operation=KeyMCertificateElement_Ssa_TrustModelEcuCert_Version_005.CertificateElementGet
        OpEventCertificateElementGetByIndex_Ssa_TrustModelRootCert_ext_pkiRole_CertificateElementGetByIndex_KeyMCertificateElem_4e86f70a: start-on-event=CertificateElementGetByIndex_Ssa_TrustModelRootCert_ext_pkiRole, operation=KeyMCertificateElement_Ssa_TrustModelRootCert_ext_pkiRole.CertificateElementGetByIndex
        OpEventCertificateElementGetByIndex_Ssa_TrustModelEcuCsr_ext_extKeyUsage_oid2_007_CertificateElementGetByIndex_KeyMCert_438a1533: start-on-event=CertificateElementGetByIndex_Ssa_TrustModelEcuCsr_ext_extKeyUsage_oid2_007, operation=KeyMCertificateElement_Ssa_TrustModelEcuCsr_ext_extKeyUsage_oid2_007.CertificateElementGetByIndex
        OpEventCertificateElementGetByIndex_Ssa_TrustModelEcuCert_validityNotBefore_005_CertificateElementGetByIndex_KeyMCertif_51e32bc4: start-on-event=CertificateElementGetByIndex_Ssa_TrustModelEcuCert_validityNotBefore_005, operation=KeyMCertificateElement_Ssa_TrustModelEcuCert_validityNotBefore_005.CertificateElementGetByIndex
        OpEventCertificateElementGetByIndex_Ssa_TrustModelIntermediatePeerCert_validityNotBefore_007_CertificateElementGetByInd_b6e52ebd: start-on-event=CertificateElementGetByIndex_Ssa_TrustModelIntermediatePeerCert_validityNotBefore_007, operation=KeyMCertificateElement_Ssa_TrustModelIntermediatePeerCert_validityNotBefore_007.CertificateElementGetByIndex
        OpEventCertificateElementGetByIndex_Ssa_TrustModelEcuCert_SubjectPublicKeyInfoAlgo_005_CertificateElementGetByIndex_Key_ddd1eccf: start-on-event=CertificateElementGetByIndex_Ssa_TrustModelEcuCert_SubjectPublicKeyInfoAlgo_005, operation=KeyMCertificateElement_Ssa_TrustModelEcuCert_SubjectPublicKeyInfoAlgo_005.CertificateElementGetByIndex
        OpEventCertElementGet_Ssa_TrustModelEcuCert_Issuer_005_CertificateElementGet_KeyMCertificateElement_Ssa_TrustModelEcuCe_9a0df525: start-on-event=CertElementGet_Ssa_TrustModelEcuCert_Issuer_005, operation=KeyMCertificateElement_Ssa_TrustModelEcuCert_Issuer_005.CertificateElementGet
        OpEventCertificateElementGetByIndex_Ssa_TrustModelEcuPeerCert_signatureValue_006_CertificateElementGetByIndex_KeyMCerti_8edbff69: start-on-event=CertificateElementGetByIndex_Ssa_TrustModelEcuPeerCert_signatureValue_006, operation=KeyMCertificateElement_Ssa_TrustModelEcuPeerCert_signatureValue_006.CertificateElementGetByIndex
        OpEventCertElementGet_Ssa_TrustModelEcuCert_signatureValue_005_CertificateElementGet_KeyMCertificateElement_Ssa_TrustMo_fd5835b5: start-on-event=CertElementGet_Ssa_TrustModelEcuCert_signatureValue_005, operation=KeyMCertificateElement_Ssa_TrustModelEcuCert_signatureValue_005.CertificateElementGet
        OpEventCertificateElementGetByIndex_Ssa_TrustModelEcuPeerCert_SubjectPublicKeyInfoAlgo_006_CertificateElementGetByIndex_e3237f1d: start-on-event=CertificateElementGetByIndex_Ssa_TrustModelEcuPeerCert_SubjectPublicKeyInfoAlgo_006, operation=KeyMCertificateElement_Ssa_TrustModelEcuPeerCert_SubjectPublicKeyInfoAlgo_006.CertificateElementGetByIndex
        OpEventCertElementGet_Ssa_TrustModelEcuCsr_Issuer_008_CertificateElementGet_KeyMCertificateElement_Ssa_TrustModelEcuCsr_d0b4b279: start-on-event=CertElementGet_Ssa_TrustModelEcuCsr_Issuer_008, operation=KeyMCertificateElement_Ssa_TrustModelEcuCsr_Issuer_008.CertificateElementGet
        OpEventCertificateElementGetByIndex_Ssa_TrustModelIntermediateCert_ext_authKeyId_003_CertificateElementGetByIndex_KeyMC_499a7f63: start-on-event=CertificateElementGetByIndex_Ssa_TrustModelIntermediateCert_ext_authKeyId_003, operation=KeyMCertificateElement_Ssa_TrustModelIntermediateCert_ext_authKeyId_003.CertificateElementGetByIndex
        OpEventCertificateElementGetByIndex_Ssa_TrustModelBackendPeerCert_signatureValue_004_CertificateElementGetByIndex_KeyMC_0fc0d881: start-on-event=CertificateElementGetByIndex_Ssa_TrustModelBackendPeerCert_signatureValue_004, operation=KeyMCertificateElement_Ssa_TrustModelBackendPeerCert_signatureValue_004.CertificateElementGetByIndex
        OpEventCertificateElementGetByIndex_Ssa_TrustModelEcuCert_signatureAlgorithm_005_CertificateElementGetByIndex_KeyMCerti_a797f84b: start-on-event=CertificateElementGetByIndex_Ssa_TrustModelEcuCert_signatureAlgorithm_005, operation=KeyMCertificateElement_Ssa_TrustModelEcuCert_signatureAlgorithm_005.CertificateElementGetByIndex
        OpEventCertificateElementGetByIndex_Ssa_TrustModelBackendCert_ext_basicConstraints_002_CertificateElementGetByIndex_Key_e24dafac: start-on-event=CertificateElementGetByIndex_Ssa_TrustModelBackendCert_ext_basicConstraints_002, operation=KeyMCertificateElement_Ssa_TrustModelBackendCert_ext_basicConstraints_002.CertificateElementGetByIndex
        OpEventCertElementGet_Ssa_TrustModelRootCert_ext_authKeyId_009_CertificateElementGet_KeyMCertificateElement_Ssa_TrustMo_9672faff: start-on-event=CertElementGet_Ssa_TrustModelRootCert_ext_authKeyId_009, operation=KeyMCertificateElement_Ssa_TrustModelRootCert_ext_authKeyId_009.CertificateElementGet
        OpEventCertElementGet_Ssa_TrustModelEcuCert_signatureAlgorithm_005_CertificateElementGet_KeyMCertificateElement_Ssa_Tru_eed066bc: start-on-event=CertElementGet_Ssa_TrustModelEcuCert_signatureAlgorithm_005, operation=KeyMCertificateElement_Ssa_TrustModelEcuCert_signatureAlgorithm_005.CertificateElementGet
        OpEventCertElementGet_Ssa_TrustModelIntermediateCert_signatureAlgorithm_003_CertificateElementGet_KeyMCertificateElemen_1e357137: start-on-event=CertElementGet_Ssa_TrustModelIntermediateCert_signatureAlgorithm_003, operation=KeyMCertificateElement_Ssa_TrustModelIntermediateCert_signatureAlgorithm_003.CertificateElementGet
        OpEventCertificateElementGetByIndex_Ssa_TrustModelEcuPeerCert_ext_specialEcu_006_CertificateElementGetByIndex_KeyMCerti_cf9234cb: start-on-event=CertificateElementGetByIndex_Ssa_TrustModelEcuPeerCert_ext_specialEcu_006, operation=KeyMCertificateElement_Ssa_TrustModelEcuPeerCert_ext_specialEcu_006.CertificateElementGetByIndex
        OpEventCertificateElementGetByIndex_Ssa_TrustModelIntermediatePeerCert_subject_007_CertificateElementGetByIndex_KeyMCer_a17f0b2d: start-on-event=CertificateElementGetByIndex_Ssa_TrustModelIntermediatePeerCert_subject_007, operation=KeyMCertificateElement_Ssa_TrustModelIntermediatePeerCert_subject_007.CertificateElementGetByIndex
        OpEventCertificateElementGetByIndex_Ssa_TrustModelIntermediateCert_subject_003_CertificateElementGetByIndex_KeyMCertifi_57b54991: start-on-event=CertificateElementGetByIndex_Ssa_TrustModelIntermediateCert_subject_003, operation=KeyMCertificateElement_Ssa_TrustModelIntermediateCert_subject_003.CertificateElementGetByIndex
        OpEventCertificateElementGetByIndex_Ssa_TrustModelIntermediateCert_Issuer_003_CertificateElementGetByIndex_KeyMCertific_2afd56af: start-on-event=CertificateElementGetByIndex_Ssa_TrustModelIntermediateCert_Issuer_003, operation=KeyMCertificateElement_Ssa_TrustModelIntermediateCert_Issuer_003.CertificateElementGetByIndex
        OpEventCertificateElementGetByIndex_Ssa_TrustModelBackendCert_subject_002_CertificateElementGetByIndex_KeyMCertificateE_7fae90a3: start-on-event=CertificateElementGetByIndex_Ssa_TrustModelBackendCert_subject_002, operation=KeyMCertificateElement_Ssa_TrustModelBackendCert_subject_002.CertificateElementGetByIndex
        OpEventCertificateElementGetByIndex_Ssa_TrustModelBackendCert_signatureValue_002_CertificateElementGetByIndex_KeyMCerti_c8393c94: start-on-event=CertificateElementGetByIndex_Ssa_TrustModelBackendCert_signatureValue_002, operation=KeyMCertificateElement_Ssa_TrustModelBackendCert_signatureValue_002.CertificateElementGetByIndex
        OpEventCertificateElementGetByIndex_Ssa_TrustModelEcuCert_Version_005_CertificateElementGetByIndex_KeyMCertificateEleme_2b52063b: start-on-event=CertificateElementGetByIndex_Ssa_TrustModelEcuCert_Version_005, operation=KeyMCertificateElement_Ssa_TrustModelEcuCert_Version_005.CertificateElementGetByIndex
        OpEventCertElementGet_Ssa_TrustModelRootCert_SigAlgoId_CertificateElementGet_KeyMCertificateElement_Ssa_TrustModelRootC_5b26c690: start-on-event=CertElementGet_Ssa_TrustModelRootCert_SigAlgoId, operation=KeyMCertificateElement_Ssa_TrustModelRootCert_SigAlgoId.CertificateElementGet
        OpEventCertElementGet_Ssa_TrustModelEcuCert_SerialNo_005_CertificateElementGet_KeyMCertificateElement_Ssa_TrustModelEcu_543e73a1: start-on-event=CertElementGet_Ssa_TrustModelEcuCert_SerialNo_005, operation=KeyMCertificateElement_Ssa_TrustModelEcuCert_SerialNo_005.CertificateElementGet
        OpEventCertificateElementGetByIndex_Ssa_TrustModelEcuCsr_ext_extKeyUsage_oid3_007_CertificateElementGetByIndex_KeyMCert_7631e948: start-on-event=CertificateElementGetByIndex_Ssa_TrustModelEcuCsr_ext_extKeyUsage_oid3_007, operation=KeyMCertificateElement_Ssa_TrustModelEcuCsr_ext_extKeyUsage_oid3_007.CertificateElementGetByIndex
        OpEventCertificateElementGetByIndex_Ssa_TrustModelEcuCsr_ext_extKeyUsage_007_CertificateElementGetByIndex_KeyMCertifica_9136e7eb: start-on-event=CertificateElementGetByIndex_Ssa_TrustModelEcuCsr_ext_extKeyUsage_007, operation=KeyMCertificateElement_Ssa_TrustModelEcuCsr_ext_extKeyUsage_007.CertificateElementGetByIndex
        OpEventCertificateElementGetByIndex_Ssa_TrustModelEcuCert_Issuer_005_CertificateElementGetByIndex_KeyMCertificateElemen_b393f67d: start-on-event=CertificateElementGetByIndex_Ssa_TrustModelEcuCert_Issuer_005, operation=KeyMCertificateElement_Ssa_TrustModelEcuCert_Issuer_005.CertificateElementGetByIndex
        OpEventCertificateElementGetByIndex_Ssa_TrustModelIntermediateCert_ext_basicConstraints_003_CertificateElementGetByInde_0165c18c: start-on-event=CertificateElementGetByIndex_Ssa_TrustModelIntermediateCert_ext_basicConstraints_003, operation=KeyMCertificateElement_Ssa_TrustModelIntermediateCert_ext_basicConstraints_003.CertificateElementGetByIndex
        OpEventCertificateElementGetByIndex_Ssa_TrustModelBackendCert_ext_subKeyId_002_CertificateElementGetByIndex_KeyMCertifi_aaa0044a: start-on-event=CertificateElementGetByIndex_Ssa_TrustModelBackendCert_ext_subKeyId_002, operation=KeyMCertificateElement_Ssa_TrustModelBackendCert_ext_subKeyId_002.CertificateElementGetByIndex
        OpEventCertElementGet_Ssa_TrustModelBackendCert_validityNotAfter_002_CertificateElementGet_KeyMCertificateElement_Ssa_T_dee6b4c9: start-on-event=CertElementGet_Ssa_TrustModelBackendCert_validityNotAfter_002, operation=KeyMCertificateElement_Ssa_TrustModelBackendCert_validityNotAfter_002.CertificateElementGet
        OpEventCertElementGet_Ssa_TrustModelEcuPeerCert_subject_006_CertificateElementGet_KeyMCertificateElement_Ssa_TrustModel_e0f85d9b: start-on-event=CertElementGet_Ssa_TrustModelEcuPeerCert_subject_006, operation=KeyMCertificateElement_Ssa_TrustModelEcuPeerCert_subject_006.CertificateElementGet
        OpEventCertificateElementGetByIndex_Ssa_TrustModelEcuCsr_Issuer_008_CertificateElementGetByIndex_KeyMCertificateElement_a458351e: start-on-event=CertificateElementGetByIndex_Ssa_TrustModelEcuCsr_Issuer_008, operation=KeyMCertificateElement_Ssa_TrustModelEcuCsr_Issuer_008.CertificateElementGetByIndex
        OpEventCertElementGet_Ssa_TrustModelIntermediatePeerCert_SubjectPublicKeyInfoAlgo_007_CertificateElementGet_KeyMCertifi_3530361a: start-on-event=CertElementGet_Ssa_TrustModelIntermediatePeerCert_SubjectPublicKeyInfoAlgo_007, operation=KeyMCertificateElement_Ssa_TrustModelIntermediatePeerCert_SubjectPublicKeyInfoAlgo_007.CertificateElementGet
        OpEventCertificateElementGetByIndex_Ssa_TrustModelEcuCert_ext_keyUsage_005_CertificateElementGetByIndex_KeyMCertificate_6565fb2a: start-on-event=CertificateElementGetByIndex_Ssa_TrustModelEcuCert_ext_keyUsage_005, operation=KeyMCertificateElement_Ssa_TrustModelEcuCert_ext_keyUsage_005.CertificateElementGetByIndex
        OpEventCertificateElementGetByIndex_Ssa_TrustModelRootCert_Version_CertificateElementGetByIndex_KeyMCertificateElement_8cca2163: start-on-event=CertificateElementGetByIndex_Ssa_TrustModelRootCert_Version, operation=KeyMCertificateElement_Ssa_TrustModelRootCert_Version.CertificateElementGetByIndex
        OpEventCertElementGet_Ssa_TrustModelEcuPeerCert_signatureValue_006_CertificateElementGet_KeyMCertificateElement_Ssa_Tru_f186f6c4: start-on-event=CertElementGet_Ssa_TrustModelEcuPeerCert_signatureValue_006, operation=KeyMCertificateElement_Ssa_TrustModelEcuPeerCert_signatureValue_006.CertificateElementGet
        OpEventCertificateElementGetByIndex_Ssa_TrustModelEcuCert_SigAlgoId_005_CertificateElementGetByIndex_KeyMCertificateEle_eeb3f9d4: start-on-event=CertificateElementGetByIndex_Ssa_TrustModelEcuCert_SigAlgoId_005, operation=KeyMCertificateElement_Ssa_TrustModelEcuCert_SigAlgoId_005.CertificateElementGetByIndex
        OpEventCertificateElementGetByIndex_Ssa_TrustModelBackendPeerCert_ext_authKeyId_004_CertificateElementGetByIndex_KeyMCe_9417c2bd: start-on-event=CertificateElementGetByIndex_Ssa_TrustModelBackendPeerCert_ext_authKeyId_004, operation=KeyMCertificateElement_Ssa_TrustModelBackendPeerCert_ext_authKeyId_004.CertificateElementGetByIndex
        OpEventCertElementGet_Ssa_TrustModelBackendPeerCert_ext_basicConstraints_004_CertificateElementGet_KeyMCertificateEleme_109578fa: start-on-event=CertElementGet_Ssa_TrustModelBackendPeerCert_ext_basicConstraints_004, operation=KeyMCertificateElement_Ssa_TrustModelBackendPeerCert_ext_basicConstraints_004.CertificateElementGet
        OpEventCertElementGet_Ssa_TrustModelIntermediatePeerCert_ext_basicConstraints_005_CertificateElementGet_KeyMCertificate_ecf0e00c: start-on-event=CertElementGet_Ssa_TrustModelIntermediatePeerCert_ext_basicConstraints_005, operation=KeyMCertificateElement_Ssa_TrustModelIntermediatePeerCert_ext_basicConstraints_005.CertificateElementGet
        OpEventCertElementGet_Ssa_TrustModelEcuCsr_ext_extKeyUsage_oid3_007_CertificateElementGet_KeyMCertificateElement_Ssa_Tr_9fa4e214: start-on-event=CertElementGet_Ssa_TrustModelEcuCsr_ext_extKeyUsage_oid3_007, operation=KeyMCertificateElement_Ssa_TrustModelEcuCsr_ext_extKeyUsage_oid3_007.CertificateElementGet
        OpEventCertificateElementGetByIndex_Ssa_TrustModelIntermediatePeerCert_ext_keyUsage_007_CertificateElementGetByIndex_Ke_b3fb2c68: start-on-event=CertificateElementGetByIndex_Ssa_TrustModelIntermediatePeerCert_ext_keyUsage_007, operation=KeyMCertificateElement_Ssa_TrustModelIntermediatePeerCert_ext_keyUsage_007.CertificateElementGetByIndex
        OpEventCertElementGet_Ssa_TrustModelIntermediateCert_SigAlgoId_003_CertificateElementGet_KeyMCertificateElement_Ssa_Tru_311a0bf1: start-on-event=CertElementGet_Ssa_TrustModelIntermediateCert_SigAlgoId_003, operation=KeyMCertificateElement_Ssa_TrustModelIntermediateCert_SigAlgoId_003.CertificateElementGet
        OpEventCertificateElementGetByIndex_Ssa_TrustModelRootCert_subject_CertificateElementGetByIndex_KeyMCertificateElement_94bc661a: start-on-event=CertificateElementGetByIndex_Ssa_TrustModelRootCert_subject, operation=KeyMCertificateElement_Ssa_TrustModelRootCert_subject.CertificateElementGetByIndex
        OpEventCertElementGet_Ssa_TrustModelIntermediateCert_ext_basicConstraints_003_CertificateElementGet_KeyMCertificateElem_ec6a31a6: start-on-event=CertElementGet_Ssa_TrustModelIntermediateCert_ext_basicConstraints_003, operation=KeyMCertificateElement_Ssa_TrustModelIntermediateCert_ext_basicConstraints_003.CertificateElementGet
        OpEventCertElementGet_Ssa_TrustModelRootCert_SubjectPublicKeyInfoAlgo_CertificateElementGet_KeyMCertificateElement_Ssa_7b23a56d: start-on-event=CertElementGet_Ssa_TrustModelRootCert_SubjectPublicKeyInfoAlgo, operation=KeyMCertificateElement_Ssa_TrustModelRootCert_SubjectPublicKeyInfoAlgo.CertificateElementGet
        OpEventCertElementGet_Ssa_TrustModelBackendPeerCert_SigAlgoId_004_CertificateElementGet_KeyMCertificateElement_Ssa_Trus_4724feee: start-on-event=CertElementGet_Ssa_TrustModelBackendPeerCert_SigAlgoId_004, operation=KeyMCertificateElement_Ssa_TrustModelBackendPeerCert_SigAlgoId_004.CertificateElementGet
        OpEventCertificateElementGetByIndex_Ssa_TrustModelRootCert_SerialNo_CertificateElementGetByIndex_KeyMCertificateElement_78ca578d: start-on-event=CertificateElementGetByIndex_Ssa_TrustModelRootCert_SerialNo, operation=KeyMCertificateElement_Ssa_TrustModelRootCert_SerialNo.CertificateElementGetByIndex
        OpEventCertificateElementGetByIndex_Ssa_TrustModelRootCert_SubjectPublicKeyInfoKey_CertificateElementGetByIndex_KeyMCer_ddcf9e15: start-on-event=CertificateElementGetByIndex_Ssa_TrustModelRootCert_SubjectPublicKeyInfoKey, operation=KeyMCertificateElement_Ssa_TrustModelRootCert_SubjectPublicKeyInfoKey.CertificateElementGetByIndex
        OpEventCertElementGet_Ssa_TrustModelEcuPeerCert_ext_subKeyId_006_CertificateElementGet_KeyMCertificateElement_Ssa_Trust_3aef5900: start-on-event=CertElementGet_Ssa_TrustModelEcuPeerCert_ext_subKeyId_006, operation=KeyMCertificateElement_Ssa_TrustModelEcuPeerCert_ext_subKeyId_006.CertificateElementGet
        OpEventCertElementGet_Ssa_TrustModelEcuCert_subject_005_CertificateElementGet_KeyMCertificateElement_Ssa_TrustModelEcuC_31a95a1a: start-on-event=CertElementGet_Ssa_TrustModelEcuCert_subject_005, operation=KeyMCertificateElement_Ssa_TrustModelEcuCert_subject_005.CertificateElementGet
        OpEventCertElementGet_Ssa_TrustModelEcuCsr_SigAlgoId_008_CertificateElementGet_KeyMCertificateElement_Ssa_TrustModelEcu_a7930dcb: start-on-event=CertElementGet_Ssa_TrustModelEcuCsr_SigAlgoId_008, operation=KeyMCertificateElement_Ssa_TrustModelEcuCsr_SigAlgoId_008.CertificateElementGet
        OpEventCertElementGet_Ssa_TrustModelBackendCert_Version_002_CertificateElementGet_KeyMCertificateElement_Ssa_TrustModel_169e830b: start-on-event=CertElementGet_Ssa_TrustModelBackendCert_Version_002, operation=KeyMCertificateElement_Ssa_TrustModelBackendCert_Version_002.CertificateElementGet
        OpEventCertificateElementGetByIndex_Ssa_TrustModelEcuCert_signatureValue_005_CertificateElementGetByIndex_KeyMCertifica_86799a00: start-on-event=CertificateElementGetByIndex_Ssa_TrustModelEcuCert_signatureValue_005, operation=KeyMCertificateElement_Ssa_TrustModelEcuCert_signatureValue_005.CertificateElementGetByIndex
        OpEventCertificateElementGetByIndex_Ssa_TrustModelBackendCert_ext_keyUsage_002_CertificateElementGetByIndex_KeyMCertifi_0f9afc00: start-on-event=CertificateElementGetByIndex_Ssa_TrustModelBackendCert_ext_keyUsage_002, operation=KeyMCertificateElement_Ssa_TrustModelBackendCert_ext_keyUsage_002.CertificateElementGetByIndex
        OpEventCertificateElementGetByIndex_Ssa_TrustModelEcuCert_validityNotAfter_005_CertificateElementGetByIndex_KeyMCertifi_ff11d730: start-on-event=CertificateElementGetByIndex_Ssa_TrustModelEcuCert_validityNotAfter_005, operation=KeyMCertificateElement_Ssa_TrustModelEcuCert_validityNotAfter_005.CertificateElementGetByIndex
        OpEventCertElementGet_Ssa_TrustModelEcuPeerCert_SubjectPublicKeyInfoKey_006_CertificateElementGet_KeyMCertificateElemen_b81305e6: start-on-event=CertElementGet_Ssa_TrustModelEcuPeerCert_SubjectPublicKeyInfoKey_006, operation=KeyMCertificateElement_Ssa_TrustModelEcuPeerCert_SubjectPublicKeyInfoKey_006.CertificateElementGet
        OpEventServiceCertificateRteWrapper_ServiceCertificate_KeyMServiceCertificate_Ssa_TrustModelEcuCert: start-on-event=ServiceCertificateRteWrapper, operation=KeyMServiceCertificate_Ssa_TrustModelEcuCert.ServiceCertificate
        OpEventServiceCertificateRteWrapper_ServiceCertificate_KeyMServiceCertificate_Ssa_TrustModelIntermediateCert: start-on-event=ServiceCertificateRteWrapper, operation=KeyMServiceCertificate_Ssa_TrustModelIntermediateCert.ServiceCertificate
        OpEventServiceCertificateRteWrapper_ServiceCertificate_KeyMServiceCertificate_Ssa_TrustModelBackendCert: start-on-event=ServiceCertificateRteWrapper, operation=KeyMServiceCertificate_Ssa_TrustModelBackendCert.ServiceCertificate
        OpEventServiceCertificateRteWrapper_ServiceCertificate_KeyMServiceCertificate_Ssa_TrustModelRootCert: start-on-event=ServiceCertificateRteWrapper, operation=KeyMServiceCertificate_Ssa_TrustModelRootCert.ServiceCertificate
        OpEventServiceCertificateRteWrapper_ServiceCertificate_KeyMServiceCertificate_Ssa_TrustModelEcuPeerCert: start-on-event=ServiceCertificateRteWrapper, operation=KeyMServiceCertificate_Ssa_TrustModelEcuPeerCert.ServiceCertificate
        OpEventServiceCertificateRteWrapper_ServiceCertificate_KeyMServiceCertificate_Ssa_TrustModelBackendPeerCert: start-on-event=ServiceCertificateRteWrapper, operation=KeyMServiceCertificate_Ssa_TrustModelBackendPeerCert.ServiceCertificate
        OpEventServiceCertificateRteWrapper_ServiceCertificate_KeyMServiceCertificate_Ssa_TrustModelIntermediatePeerCert: start-on-event=ServiceCertificateRteWrapper, operation=KeyMServiceCertificate_Ssa_TrustModelIntermediatePeerCert.ServiceCertificate
        OpEventServiceCertificateRteWrapper_ServiceCertificate_KeyMServiceCertificate_Ssa_TrustModelEcuCsr: start-on-event=ServiceCertificateRteWrapper, operation=KeyMServiceCertificate_Ssa_TrustModelEcuCsr.ServiceCertificate
        OpEventServiceCertificateByCertIdRteWrapper_ServiceCertificateByCertId_KeyMServiceCertificateByCertId_Ssa_TrustModelEcuCert: start-on-event=ServiceCertificateByCertIdRteWrapper, operation=KeyMServiceCertificateByCertId_Ssa_TrustModelEcuCert.ServiceCertificateByCertId
        OpEventServiceCertificateByCertIdRteWrapper_ServiceCertificateByCertId_KeyMServiceCertificateByCertId_Ssa_TrustModelInt_28f10efd: start-on-event=ServiceCertificateByCertIdRteWrapper, operation=KeyMServiceCertificateByCertId_Ssa_TrustModelIntermediateCert.ServiceCertificateByCertId
        OpEventServiceCertificateByCertIdRteWrapper_ServiceCertificateByCertId_KeyMServiceCertificateByCertId_Ssa_TrustModelBackendCert: start-on-event=ServiceCertificateByCertIdRteWrapper, operation=KeyMServiceCertificateByCertId_Ssa_TrustModelBackendCert.ServiceCertificateByCertId
        OpEventServiceCertificateByCertIdRteWrapper_ServiceCertificateByCertId_KeyMServiceCertificateByCertId_Ssa_TrustModelRootCert: start-on-event=ServiceCertificateByCertIdRteWrapper, operation=KeyMServiceCertificateByCertId_Ssa_TrustModelRootCert.ServiceCertificateByCertId
        OpEventServiceCertificateByCertIdRteWrapper_ServiceCertificateByCertId_KeyMServiceCertificateByCertId_Ssa_TrustModelEcuPeerCert: start-on-event=ServiceCertificateByCertIdRteWrapper, operation=KeyMServiceCertificateByCertId_Ssa_TrustModelEcuPeerCert.ServiceCertificateByCertId
        OpEventServiceCertificateByCertIdRteWrapper_ServiceCertificateByCertId_KeyMServiceCertificateByCertId_Ssa_TrustModelBac_a8f767a0: start-on-event=ServiceCertificateByCertIdRteWrapper, operation=KeyMServiceCertificateByCertId_Ssa_TrustModelBackendPeerCert.ServiceCertificateByCertId
        OpEventServiceCertificateByCertIdRteWrapper_ServiceCertificateByCertId_KeyMServiceCertificateByCertId_Ssa_TrustModelInt_89bfe568: start-on-event=ServiceCertificateByCertIdRteWrapper, operation=KeyMServiceCertificateByCertId_Ssa_TrustModelIntermediatePeerCert.ServiceCertificateByCertId
        OpEventServiceCertificateByCertIdRteWrapper_ServiceCertificateByCertId_KeyMServiceCertificateByCertId_Ssa_TrustModelEcuCsr: start-on-event=ServiceCertificateByCertIdRteWrapper, operation=KeyMServiceCertificateByCertId_Ssa_TrustModelEcuCsr.ServiceCertificateByCertId
